VERSION ""

NS_ :

BS_:

BU_:

BO_ 65 FRS_Obj_Part2of2_Copy_39: 8 Vector__XXX
 SG_ FRS_Msg_CheckSum : 63|8@0+ (1,0) [0|255] "" Vector__XXX
 SG_ FRS_Msg_AliveCounter : 51|4@0+ (1,0) [0|15] "" Vector__XXX
 SG_ FRS_Obj_MeasFlag : 52|1@0+ (1,0) [0|1] "" Vector__XXX
 SG_ FRS_Obj_YVelRel : 47|11@0+ (0.1,-102.4) [-102.4|102.3] "m/s" Vector__XXX
 SG_ FRS_Obj_Type : 33|2@0+ (1,0) [0|3] "" Vector__XXX
 SG_ FRS_Obj_XPos : 31|14@0+ (0.015625,0) [0|255.984375] "m" Vector__XXX
 SG_ FRS_Obj_YPos : 12|13@0+ (0.015625,-64) [-64|63.984375] "m" Vector__XXX
 SG_ FRS_Obj_XVelRel : 7|11@0+ (0.1,-102.4) [-102.4|102.3] "m/s" Vector__XXX

BO_ 64 FRS_Obj_Part2of2_Copy_38: 8 Vector__XXX
 SG_ FRS_Msg_CheckSum : 63|8@0+ (1,0) [0|255] "" Vector__XXX
 SG_ FRS_Msg_AliveCounter : 51|4@0+ (1,0) [0|15] "" Vector__XXX
 SG_ FRS_Obj_MeasFlag : 52|1@0+ (1,0) [0|1] "" Vector__XXX
 SG_ FRS_Obj_YVelRel : 47|11@0+ (0.1,-102.4) [-102.4|102.3] "m/s" Vector__XXX
 SG_ FRS_Obj_Type : 33|2@0+ (1,0) [0|3] "" Vector__XXX
 SG_ FRS_Obj_XPos : 31|14@0+ (0.015625,0) [0|255.984375] "m" Vector__XXX
 SG_ FRS_Obj_YPos : 12|13@0+ (0.015625,-64) [-64|63.984375] "m" Vector__XXX
 SG_ FRS_Obj_XVelRel : 7|11@0+ (0.1,-102.4) [-102.4|102.3] "m/s" Vector__XXX

BO_ 63 FRS_Obj_Part2of2_Copy_37: 8 Vector__XXX
 SG_ FRS_Msg_CheckSum : 63|8@0+ (1,0) [0|255] "" Vector__XXX
 SG_ FRS_Msg_AliveCounter : 51|4@0+ (1,0) [0|15] "" Vector__XXX
 SG_ FRS_Obj_MeasFlag : 52|1@0+ (1,0) [0|1] "" Vector__XXX
 SG_ FRS_Obj_YVelRel : 47|11@0+ (0.1,-102.4) [-102.4|102.3] "m/s" Vector__XXX
 SG_ FRS_Obj_Type : 33|2@0+ (1,0) [0|3] "" Vector__XXX
 SG_ FRS_Obj_XPos : 31|14@0+ (0.015625,0) [0|255.984375] "m" Vector__XXX
 SG_ FRS_Obj_YPos : 12|13@0+ (0.015625,-64) [-64|63.984375] "m" Vector__XXX
 SG_ FRS_Obj_XVelRel : 7|11@0+ (0.1,-102.4) [-102.4|102.3] "m/s" Vector__XXX

BO_ 62 FRS_Obj_Part2of2_Copy_36: 8 Vector__XXX
 SG_ FRS_Msg_CheckSum : 63|8@0+ (1,0) [0|255] "" Vector__XXX
 SG_ FRS_Msg_AliveCounter : 51|4@0+ (1,0) [0|15] "" Vector__XXX
 SG_ FRS_Obj_MeasFlag : 52|1@0+ (1,0) [0|1] "" Vector__XXX
 SG_ FRS_Obj_YVelRel : 47|11@0+ (0.1,-102.4) [-102.4|102.3] "m/s" Vector__XXX
 SG_ FRS_Obj_Type : 33|2@0+ (1,0) [0|3] "" Vector__XXX
 SG_ FRS_Obj_XPos : 31|14@0+ (0.015625,0) [0|255.984375] "m" Vector__XXX
 SG_ FRS_Obj_YPos : 12|13@0+ (0.015625,-64) [-64|63.984375] "m" Vector__XXX
 SG_ FRS_Obj_XVelRel : 7|11@0+ (0.1,-102.4) [-102.4|102.3] "m/s" Vector__XXX

BO_ 61 FRS_Obj_Part2of2_Copy_35: 8 Vector__XXX
 SG_ FRS_Msg_CheckSum : 63|8@0+ (1,0) [0|255] "" Vector__XXX
 SG_ FRS_Msg_AliveCounter : 51|4@0+ (1,0) [0|15] "" Vector__XXX
 SG_ FRS_Obj_MeasFlag : 52|1@0+ (1,0) [0|1] "" Vector__XXX
 SG_ FRS_Obj_YVelRel : 47|11@0+ (0.1,-102.4) [-102.4|102.3] "m/s" Vector__XXX
 SG_ FRS_Obj_Type : 33|2@0+ (1,0) [0|3] "" Vector__XXX
 SG_ FRS_Obj_XPos : 31|14@0+ (0.015625,0) [0|255.984375] "m" Vector__XXX
 SG_ FRS_Obj_YPos : 12|13@0+ (0.015625,-64) [-64|63.984375] "m" Vector__XXX
 SG_ FRS_Obj_XVelRel : 7|11@0+ (0.1,-102.4) [-102.4|102.3] "m/s" Vector__XXX

BO_ 60 FRS_Obj_Part2of2_Copy_34: 8 Vector__XXX
 SG_ FRS_Msg_CheckSum : 63|8@0+ (1,0) [0|255] "" Vector__XXX
 SG_ FRS_Msg_AliveCounter : 51|4@0+ (1,0) [0|15] "" Vector__XXX
 SG_ FRS_Obj_MeasFlag : 52|1@0+ (1,0) [0|1] "" Vector__XXX
 SG_ FRS_Obj_YVelRel : 47|11@0+ (0.1,-102.4) [-102.4|102.3] "m/s" Vector__XXX
 SG_ FRS_Obj_Type : 33|2@0+ (1,0) [0|3] "" Vector__XXX
 SG_ FRS_Obj_XPos : 31|14@0+ (0.015625,0) [0|255.984375] "m" Vector__XXX
 SG_ FRS_Obj_YPos : 12|13@0+ (0.015625,-64) [-64|63.984375] "m" Vector__XXX
 SG_ FRS_Obj_XVelRel : 7|11@0+ (0.1,-102.4) [-102.4|102.3] "m/s" Vector__XXX

BO_ 59 FRS_Obj_Part2of2_Copy_33: 8 Vector__XXX
 SG_ FRS_Msg_CheckSum : 63|8@0+ (1,0) [0|255] "" Vector__XXX
 SG_ FRS_Msg_AliveCounter : 51|4@0+ (1,0) [0|15] "" Vector__XXX
 SG_ FRS_Obj_MeasFlag : 52|1@0+ (1,0) [0|1] "" Vector__XXX
 SG_ FRS_Obj_YVelRel : 47|11@0+ (0.1,-102.4) [-102.4|102.3] "m/s" Vector__XXX
 SG_ FRS_Obj_Type : 33|2@0+ (1,0) [0|3] "" Vector__XXX
 SG_ FRS_Obj_XPos : 31|14@0+ (0.015625,0) [0|255.984375] "m" Vector__XXX
 SG_ FRS_Obj_YPos : 12|13@0+ (0.015625,-64) [-64|63.984375] "m" Vector__XXX
 SG_ FRS_Obj_XVelRel : 7|11@0+ (0.1,-102.4) [-102.4|102.3] "m/s" Vector__XXX

BO_ 58 FRS_Obj_Part2of2_Copy_32: 8 Vector__XXX
 SG_ FRS_Msg_CheckSum : 63|8@0+ (1,0) [0|255] "" Vector__XXX
 SG_ FRS_Msg_AliveCounter : 51|4@0+ (1,0) [0|15] "" Vector__XXX
 SG_ FRS_Obj_MeasFlag : 52|1@0+ (1,0) [0|1] "" Vector__XXX
 SG_ FRS_Obj_YVelRel : 47|11@0+ (0.1,-102.4) [-102.4|102.3] "m/s" Vector__XXX
 SG_ FRS_Obj_Type : 33|2@0+ (1,0) [0|3] "" Vector__XXX
 SG_ FRS_Obj_XPos : 31|14@0+ (0.015625,0) [0|255.984375] "m" Vector__XXX
 SG_ FRS_Obj_YPos : 12|13@0+ (0.015625,-64) [-64|63.984375] "m" Vector__XXX
 SG_ FRS_Obj_XVelRel : 7|11@0+ (0.1,-102.4) [-102.4|102.3] "m/s" Vector__XXX

BO_ 57 FRS_Obj_Part2of2_Copy_31: 8 Vector__XXX
 SG_ FRS_Msg_CheckSum : 63|8@0+ (1,0) [0|255] "" Vector__XXX
 SG_ FRS_Msg_AliveCounter : 51|4@0+ (1,0) [0|15] "" Vector__XXX
 SG_ FRS_Obj_MeasFlag : 52|1@0+ (1,0) [0|1] "" Vector__XXX
 SG_ FRS_Obj_YVelRel : 47|11@0+ (0.1,-102.4) [-102.4|102.3] "m/s" Vector__XXX
 SG_ FRS_Obj_Type : 33|2@0+ (1,0) [0|3] "" Vector__XXX
 SG_ FRS_Obj_XPos : 31|14@0+ (0.015625,0) [0|255.984375] "m" Vector__XXX
 SG_ FRS_Obj_YPos : 12|13@0+ (0.015625,-64) [-64|63.984375] "m" Vector__XXX
 SG_ FRS_Obj_XVelRel : 7|11@0+ (0.1,-102.4) [-102.4|102.3] "m/s" Vector__XXX

BO_ 56 FRS_Obj_Part2of2_Copy_30: 8 Vector__XXX
 SG_ FRS_Msg_CheckSum : 63|8@0+ (1,0) [0|255] "" Vector__XXX
 SG_ FRS_Msg_AliveCounter : 51|4@0+ (1,0) [0|15] "" Vector__XXX
 SG_ FRS_Obj_MeasFlag : 52|1@0+ (1,0) [0|1] "" Vector__XXX
 SG_ FRS_Obj_YVelRel : 47|11@0+ (0.1,-102.4) [-102.4|102.3] "m/s" Vector__XXX
 SG_ FRS_Obj_Type : 33|2@0+ (1,0) [0|3] "" Vector__XXX
 SG_ FRS_Obj_XPos : 31|14@0+ (0.015625,0) [0|255.984375] "m" Vector__XXX
 SG_ FRS_Obj_YPos : 12|13@0+ (0.015625,-64) [-64|63.984375] "m" Vector__XXX
 SG_ FRS_Obj_XVelRel : 7|11@0+ (0.1,-102.4) [-102.4|102.3] "m/s" Vector__XXX

BO_ 54 FRS_Obj_Part2of2_Copy_29: 8 Vector__XXX
 SG_ FRS_Msg_CheckSum : 63|8@0+ (1,0) [0|255] "" Vector__XXX
 SG_ FRS_Msg_AliveCounter : 51|4@0+ (1,0) [0|15] "" Vector__XXX
 SG_ FRS_Obj_MeasFlag : 52|1@0+ (1,0) [0|1] "" Vector__XXX
 SG_ FRS_Obj_YVelRel : 47|11@0+ (0.1,-102.4) [-102.4|102.3] "m/s" Vector__XXX
 SG_ FRS_Obj_Type : 33|2@0+ (1,0) [0|3] "" Vector__XXX
 SG_ FRS_Obj_XPos : 31|14@0+ (0.015625,0) [0|255.984375] "m" Vector__XXX
 SG_ FRS_Obj_YPos : 12|13@0+ (0.015625,-64) [-64|63.984375] "m" Vector__XXX
 SG_ FRS_Obj_XVelRel : 7|11@0+ (0.1,-102.4) [-102.4|102.3] "m/s" Vector__XXX

BO_ 53 FRS_Obj_Part2of2_Copy_28: 8 Vector__XXX
 SG_ FRS_Msg_CheckSum : 63|8@0+ (1,0) [0|255] "" Vector__XXX
 SG_ FRS_Msg_AliveCounter : 51|4@0+ (1,0) [0|15] "" Vector__XXX
 SG_ FRS_Obj_MeasFlag : 52|1@0+ (1,0) [0|1] "" Vector__XXX
 SG_ FRS_Obj_YVelRel : 47|11@0+ (0.1,-102.4) [-102.4|102.3] "m/s" Vector__XXX
 SG_ FRS_Obj_Type : 33|2@0+ (1,0) [0|3] "" Vector__XXX
 SG_ FRS_Obj_XPos : 31|14@0+ (0.015625,0) [0|255.984375] "m" Vector__XXX
 SG_ FRS_Obj_YPos : 12|13@0+ (0.015625,-64) [-64|63.984375] "m" Vector__XXX
 SG_ FRS_Obj_XVelRel : 7|11@0+ (0.1,-102.4) [-102.4|102.3] "m/s" Vector__XXX

BO_ 52 FRS_Obj_Part2of2_Copy_27: 8 Vector__XXX
 SG_ FRS_Msg_CheckSum : 63|8@0+ (1,0) [0|255] "" Vector__XXX
 SG_ FRS_Msg_AliveCounter : 51|4@0+ (1,0) [0|15] "" Vector__XXX
 SG_ FRS_Obj_MeasFlag : 52|1@0+ (1,0) [0|1] "" Vector__XXX
 SG_ FRS_Obj_YVelRel : 47|11@0+ (0.1,-102.4) [-102.4|102.3] "m/s" Vector__XXX
 SG_ FRS_Obj_Type : 33|2@0+ (1,0) [0|3] "" Vector__XXX
 SG_ FRS_Obj_XPos : 31|14@0+ (0.015625,0) [0|255.984375] "m" Vector__XXX
 SG_ FRS_Obj_YPos : 12|13@0+ (0.015625,-64) [-64|63.984375] "m" Vector__XXX
 SG_ FRS_Obj_XVelRel : 7|11@0+ (0.1,-102.4) [-102.4|102.3] "m/s" Vector__XXX

BO_ 51 FRS_Obj_Part2of2_Copy_26: 8 Vector__XXX
 SG_ FRS_Msg_CheckSum : 63|8@0+ (1,0) [0|255] "" Vector__XXX
 SG_ FRS_Msg_AliveCounter : 51|4@0+ (1,0) [0|15] "" Vector__XXX
 SG_ FRS_Obj_MeasFlag : 52|1@0+ (1,0) [0|1] "" Vector__XXX
 SG_ FRS_Obj_YVelRel : 47|11@0+ (0.1,-102.4) [-102.4|102.3] "m/s" Vector__XXX
 SG_ FRS_Obj_Type : 33|2@0+ (1,0) [0|3] "" Vector__XXX
 SG_ FRS_Obj_XPos : 31|14@0+ (0.015625,0) [0|255.984375] "m" Vector__XXX
 SG_ FRS_Obj_YPos : 12|13@0+ (0.015625,-64) [-64|63.984375] "m" Vector__XXX
 SG_ FRS_Obj_XVelRel : 7|11@0+ (0.1,-102.4) [-102.4|102.3] "m/s" Vector__XXX

BO_ 50 FRS_Obj_Part2of2_Copy_25: 8 Vector__XXX
 SG_ FRS_Msg_CheckSum : 63|8@0+ (1,0) [0|255] "" Vector__XXX
 SG_ FRS_Msg_AliveCounter : 51|4@0+ (1,0) [0|15] "" Vector__XXX
 SG_ FRS_Obj_MeasFlag : 52|1@0+ (1,0) [0|1] "" Vector__XXX
 SG_ FRS_Obj_YVelRel : 47|11@0+ (0.1,-102.4) [-102.4|102.3] "m/s" Vector__XXX
 SG_ FRS_Obj_Type : 33|2@0+ (1,0) [0|3] "" Vector__XXX
 SG_ FRS_Obj_XPos : 31|14@0+ (0.015625,0) [0|255.984375] "m" Vector__XXX
 SG_ FRS_Obj_YPos : 12|13@0+ (0.015625,-64) [-64|63.984375] "m" Vector__XXX
 SG_ FRS_Obj_XVelRel : 7|11@0+ (0.1,-102.4) [-102.4|102.3] "m/s" Vector__XXX

BO_ 49 FRS_Obj_Part2of2_Copy_24: 8 Vector__XXX
 SG_ FRS_Msg_CheckSum : 63|8@0+ (1,0) [0|255] "" Vector__XXX
 SG_ FRS_Msg_AliveCounter : 51|4@0+ (1,0) [0|15] "" Vector__XXX
 SG_ FRS_Obj_MeasFlag : 52|1@0+ (1,0) [0|1] "" Vector__XXX
 SG_ FRS_Obj_YVelRel : 47|11@0+ (0.1,-102.4) [-102.4|102.3] "m/s" Vector__XXX
 SG_ FRS_Obj_Type : 33|2@0+ (1,0) [0|3] "" Vector__XXX
 SG_ FRS_Obj_XPos : 31|14@0+ (0.015625,0) [0|255.984375] "m" Vector__XXX
 SG_ FRS_Obj_YPos : 12|13@0+ (0.015625,-64) [-64|63.984375] "m" Vector__XXX
 SG_ FRS_Obj_XVelRel : 7|11@0+ (0.1,-102.4) [-102.4|102.3] "m/s" Vector__XXX

BO_ 48 FRS_Obj_Part2of2_Copy_23: 8 Vector__XXX
 SG_ FRS_Msg_CheckSum : 63|8@0+ (1,0) [0|255] "" Vector__XXX
 SG_ FRS_Msg_AliveCounter : 51|4@0+ (1,0) [0|15] "" Vector__XXX
 SG_ FRS_Obj_MeasFlag : 52|1@0+ (1,0) [0|1] "" Vector__XXX
 SG_ FRS_Obj_YVelRel : 47|11@0+ (0.1,-102.4) [-102.4|102.3] "m/s" Vector__XXX
 SG_ FRS_Obj_Type : 33|2@0+ (1,0) [0|3] "" Vector__XXX
 SG_ FRS_Obj_XPos : 31|14@0+ (0.015625,0) [0|255.984375] "m" Vector__XXX
 SG_ FRS_Obj_YPos : 12|13@0+ (0.015625,-64) [-64|63.984375] "m" Vector__XXX
 SG_ FRS_Obj_XVelRel : 7|11@0+ (0.1,-102.4) [-102.4|102.3] "m/s" Vector__XXX

BO_ 47 FRS_Obj_Part2of2_Copy_22: 8 Vector__XXX
 SG_ FRS_Msg_CheckSum : 63|8@0+ (1,0) [0|255] "" Vector__XXX
 SG_ FRS_Msg_AliveCounter : 51|4@0+ (1,0) [0|15] "" Vector__XXX
 SG_ FRS_Obj_MeasFlag : 52|1@0+ (1,0) [0|1] "" Vector__XXX
 SG_ FRS_Obj_YVelRel : 47|11@0+ (0.1,-102.4) [-102.4|102.3] "m/s" Vector__XXX
 SG_ FRS_Obj_Type : 33|2@0+ (1,0) [0|3] "" Vector__XXX
 SG_ FRS_Obj_XPos : 31|14@0+ (0.015625,0) [0|255.984375] "m" Vector__XXX
 SG_ FRS_Obj_YPos : 12|13@0+ (0.015625,-64) [-64|63.984375] "m" Vector__XXX
 SG_ FRS_Obj_XVelRel : 7|11@0+ (0.1,-102.4) [-102.4|102.3] "m/s" Vector__XXX

BO_ 46 FRS_Obj_Part2of2_Copy_21: 8 Vector__XXX
 SG_ FRS_Msg_CheckSum : 63|8@0+ (1,0) [0|255] "" Vector__XXX
 SG_ FRS_Msg_AliveCounter : 51|4@0+ (1,0) [0|15] "" Vector__XXX
 SG_ FRS_Obj_MeasFlag : 52|1@0+ (1,0) [0|1] "" Vector__XXX
 SG_ FRS_Obj_YVelRel : 47|11@0+ (0.1,-102.4) [-102.4|102.3] "m/s" Vector__XXX
 SG_ FRS_Obj_Type : 33|2@0+ (1,0) [0|3] "" Vector__XXX
 SG_ FRS_Obj_XPos : 31|14@0+ (0.015625,0) [0|255.984375] "m" Vector__XXX
 SG_ FRS_Obj_YPos : 12|13@0+ (0.015625,-64) [-64|63.984375] "m" Vector__XXX
 SG_ FRS_Obj_XVelRel : 7|11@0+ (0.1,-102.4) [-102.4|102.3] "m/s" Vector__XXX

BO_ 45 FRS_Obj_Part2of2_Copy_20: 8 Vector__XXX
 SG_ FRS_Msg_CheckSum : 63|8@0+ (1,0) [0|255] "" Vector__XXX
 SG_ FRS_Msg_AliveCounter : 51|4@0+ (1,0) [0|15] "" Vector__XXX
 SG_ FRS_Obj_MeasFlag : 52|1@0+ (1,0) [0|1] "" Vector__XXX
 SG_ FRS_Obj_YVelRel : 47|11@0+ (0.1,-102.4) [-102.4|102.3] "m/s" Vector__XXX
 SG_ FRS_Obj_Type : 33|2@0+ (1,0) [0|3] "" Vector__XXX
 SG_ FRS_Obj_XPos : 31|14@0+ (0.015625,0) [0|255.984375] "m" Vector__XXX
 SG_ FRS_Obj_YPos : 12|13@0+ (0.015625,-64) [-64|63.984375] "m" Vector__XXX
 SG_ FRS_Obj_XVelRel : 7|11@0+ (0.1,-102.4) [-102.4|102.3] "m/s" Vector__XXX

BO_ 43 FRS_Obj_Part2of2_Copy_19: 8 Vector__XXX
 SG_ FRS_Msg_CheckSum : 63|8@0+ (1,0) [0|255] "" Vector__XXX
 SG_ FRS_Msg_AliveCounter : 51|4@0+ (1,0) [0|15] "" Vector__XXX
 SG_ FRS_Obj_MeasFlag : 52|1@0+ (1,0) [0|1] "" Vector__XXX
 SG_ FRS_Obj_YVelRel : 47|11@0+ (0.1,-102.4) [-102.4|102.3] "m/s" Vector__XXX
 SG_ FRS_Obj_Type : 33|2@0+ (1,0) [0|3] "" Vector__XXX
 SG_ FRS_Obj_XPos : 31|14@0+ (0.015625,0) [0|255.984375] "m" Vector__XXX
 SG_ FRS_Obj_YPos : 12|13@0+ (0.015625,-64) [-64|63.984375] "m" Vector__XXX
 SG_ FRS_Obj_XVelRel : 7|11@0+ (0.1,-102.4) [-102.4|102.3] "m/s" Vector__XXX

BO_ 42 FRS_Obj_Part2of2_Copy_18: 8 Vector__XXX
 SG_ FRS_Msg_CheckSum : 63|8@0+ (1,0) [0|255] "" Vector__XXX
 SG_ FRS_Msg_AliveCounter : 51|4@0+ (1,0) [0|15] "" Vector__XXX
 SG_ FRS_Obj_MeasFlag : 52|1@0+ (1,0) [0|1] "" Vector__XXX
 SG_ FRS_Obj_YVelRel : 47|11@0+ (0.1,-102.4) [-102.4|102.3] "m/s" Vector__XXX
 SG_ FRS_Obj_Type : 33|2@0+ (1,0) [0|3] "" Vector__XXX
 SG_ FRS_Obj_XPos : 31|14@0+ (0.015625,0) [0|255.984375] "m" Vector__XXX
 SG_ FRS_Obj_YPos : 12|13@0+ (0.015625,-64) [-64|63.984375] "m" Vector__XXX
 SG_ FRS_Obj_XVelRel : 7|11@0+ (0.1,-102.4) [-102.4|102.3] "m/s" Vector__XXX

BO_ 41 FRS_Obj_Part2of2_Copy_17: 8 Vector__XXX
 SG_ FRS_Msg_CheckSum : 63|8@0+ (1,0) [0|255] "" Vector__XXX
 SG_ FRS_Msg_AliveCounter : 51|4@0+ (1,0) [0|15] "" Vector__XXX
 SG_ FRS_Obj_MeasFlag : 52|1@0+ (1,0) [0|1] "" Vector__XXX
 SG_ FRS_Obj_YVelRel : 47|11@0+ (0.1,-102.4) [-102.4|102.3] "m/s" Vector__XXX
 SG_ FRS_Obj_Type : 33|2@0+ (1,0) [0|3] "" Vector__XXX
 SG_ FRS_Obj_XPos : 31|14@0+ (0.015625,0) [0|255.984375] "m" Vector__XXX
 SG_ FRS_Obj_YPos : 12|13@0+ (0.015625,-64) [-64|63.984375] "m" Vector__XXX
 SG_ FRS_Obj_XVelRel : 7|11@0+ (0.1,-102.4) [-102.4|102.3] "m/s" Vector__XXX

BO_ 40 FRS_Obj_Part2of2_Copy_16: 8 Vector__XXX
 SG_ FRS_Msg_CheckSum : 63|8@0+ (1,0) [0|255] "" Vector__XXX
 SG_ FRS_Msg_AliveCounter : 51|4@0+ (1,0) [0|15] "" Vector__XXX
 SG_ FRS_Obj_MeasFlag : 52|1@0+ (1,0) [0|1] "" Vector__XXX
 SG_ FRS_Obj_YVelRel : 47|11@0+ (0.1,-102.4) [-102.4|102.3] "m/s" Vector__XXX
 SG_ FRS_Obj_Type : 33|2@0+ (1,0) [0|3] "" Vector__XXX
 SG_ FRS_Obj_XPos : 31|14@0+ (0.015625,0) [0|255.984375] "m" Vector__XXX
 SG_ FRS_Obj_YPos : 12|13@0+ (0.015625,-64) [-64|63.984375] "m" Vector__XXX
 SG_ FRS_Obj_XVelRel : 7|11@0+ (0.1,-102.4) [-102.4|102.3] "m/s" Vector__XXX

BO_ 39 FRS_Obj_Part2of2_Copy_15: 8 Vector__XXX
 SG_ FRS_Msg_CheckSum : 63|8@0+ (1,0) [0|255] "" Vector__XXX
 SG_ FRS_Msg_AliveCounter : 51|4@0+ (1,0) [0|15] "" Vector__XXX
 SG_ FRS_Obj_MeasFlag : 52|1@0+ (1,0) [0|1] "" Vector__XXX
 SG_ FRS_Obj_YVelRel : 47|11@0+ (0.1,-102.4) [-102.4|102.3] "m/s" Vector__XXX
 SG_ FRS_Obj_Type : 33|2@0+ (1,0) [0|3] "" Vector__XXX
 SG_ FRS_Obj_XPos : 31|14@0+ (0.015625,0) [0|255.984375] "m" Vector__XXX
 SG_ FRS_Obj_YPos : 12|13@0+ (0.015625,-64) [-64|63.984375] "m" Vector__XXX
 SG_ FRS_Obj_XVelRel : 7|11@0+ (0.1,-102.4) [-102.4|102.3] "m/s" Vector__XXX

BO_ 38 FRS_Obj_Part2of2_Copy_14: 8 Vector__XXX
 SG_ FRS_Msg_CheckSum : 63|8@0+ (1,0) [0|255] "" Vector__XXX
 SG_ FRS_Msg_AliveCounter : 51|4@0+ (1,0) [0|15] "" Vector__XXX
 SG_ FRS_Obj_MeasFlag : 52|1@0+ (1,0) [0|1] "" Vector__XXX
 SG_ FRS_Obj_YVelRel : 47|11@0+ (0.1,-102.4) [-102.4|102.3] "m/s" Vector__XXX
 SG_ FRS_Obj_Type : 33|2@0+ (1,0) [0|3] "" Vector__XXX
 SG_ FRS_Obj_XPos : 31|14@0+ (0.015625,0) [0|255.984375] "m" Vector__XXX
 SG_ FRS_Obj_YPos : 12|13@0+ (0.015625,-64) [-64|63.984375] "m" Vector__XXX
 SG_ FRS_Obj_XVelRel : 7|11@0+ (0.1,-102.4) [-102.4|102.3] "m/s" Vector__XXX

BO_ 37 FRS_Obj_Part2of2_Copy_13: 8 Vector__XXX
 SG_ FRS_Msg_CheckSum : 63|8@0+ (1,0) [0|255] "" Vector__XXX
 SG_ FRS_Msg_AliveCounter : 51|4@0+ (1,0) [0|15] "" Vector__XXX
 SG_ FRS_Obj_MeasFlag : 52|1@0+ (1,0) [0|1] "" Vector__XXX
 SG_ FRS_Obj_YVelRel : 47|11@0+ (0.1,-102.4) [-102.4|102.3] "m/s" Vector__XXX
 SG_ FRS_Obj_Type : 33|2@0+ (1,0) [0|3] "" Vector__XXX
 SG_ FRS_Obj_XPos : 31|14@0+ (0.015625,0) [0|255.984375] "m" Vector__XXX
 SG_ FRS_Obj_YPos : 12|13@0+ (0.015625,-64) [-64|63.984375] "m" Vector__XXX
 SG_ FRS_Obj_XVelRel : 7|11@0+ (0.1,-102.4) [-102.4|102.3] "m/s" Vector__XXX

BO_ 36 FRS_Obj_Part2of2_Copy_12: 8 Vector__XXX
 SG_ FRS_Msg_CheckSum : 63|8@0+ (1,0) [0|255] "" Vector__XXX
 SG_ FRS_Msg_AliveCounter : 51|4@0+ (1,0) [0|15] "" Vector__XXX
 SG_ FRS_Obj_MeasFlag : 52|1@0+ (1,0) [0|1] "" Vector__XXX
 SG_ FRS_Obj_YVelRel : 47|11@0+ (0.1,-102.4) [-102.4|102.3] "m/s" Vector__XXX
 SG_ FRS_Obj_Type : 33|2@0+ (1,0) [0|3] "" Vector__XXX
 SG_ FRS_Obj_XPos : 31|14@0+ (0.015625,0) [0|255.984375] "m" Vector__XXX
 SG_ FRS_Obj_YPos : 12|13@0+ (0.015625,-64) [-64|63.984375] "m" Vector__XXX
 SG_ FRS_Obj_XVelRel : 7|11@0+ (0.1,-102.4) [-102.4|102.3] "m/s" Vector__XXX

BO_ 35 FRS_Obj_Part2of2_Copy_11: 8 Vector__XXX
 SG_ FRS_Msg_CheckSum : 63|8@0+ (1,0) [0|255] "" Vector__XXX
 SG_ FRS_Msg_AliveCounter : 51|4@0+ (1,0) [0|15] "" Vector__XXX
 SG_ FRS_Obj_MeasFlag : 52|1@0+ (1,0) [0|1] "" Vector__XXX
 SG_ FRS_Obj_YVelRel : 47|11@0+ (0.1,-102.4) [-102.4|102.3] "m/s" Vector__XXX
 SG_ FRS_Obj_Type : 33|2@0+ (1,0) [0|3] "" Vector__XXX
 SG_ FRS_Obj_XPos : 31|14@0+ (0.015625,0) [0|255.984375] "m" Vector__XXX
 SG_ FRS_Obj_YPos : 12|13@0+ (0.015625,-64) [-64|63.984375] "m" Vector__XXX
 SG_ FRS_Obj_XVelRel : 7|11@0+ (0.1,-102.4) [-102.4|102.3] "m/s" Vector__XXX

BO_ 34 FRS_Obj_Part2of2_Copy_10: 8 Vector__XXX
 SG_ FRS_Msg_CheckSum : 63|8@0+ (1,0) [0|255] "" Vector__XXX
 SG_ FRS_Msg_AliveCounter : 51|4@0+ (1,0) [0|15] "" Vector__XXX
 SG_ FRS_Obj_MeasFlag : 52|1@0+ (1,0) [0|1] "" Vector__XXX
 SG_ FRS_Obj_YVelRel : 47|11@0+ (0.1,-102.4) [-102.4|102.3] "m/s" Vector__XXX
 SG_ FRS_Obj_Type : 33|2@0+ (1,0) [0|3] "" Vector__XXX
 SG_ FRS_Obj_XPos : 31|14@0+ (0.015625,0) [0|255.984375] "m" Vector__XXX
 SG_ FRS_Obj_YPos : 12|13@0+ (0.015625,-64) [-64|63.984375] "m" Vector__XXX
 SG_ FRS_Obj_XVelRel : 7|11@0+ (0.1,-102.4) [-102.4|102.3] "m/s" Vector__XXX

BO_ 71 FRS_Obj_Part2of2_Copy_9: 8 Vector__XXX
 SG_ FRS_Msg_CheckSum : 63|8@0+ (1,0) [0|255] "" Vector__XXX
 SG_ FRS_Msg_AliveCounter : 51|4@0+ (1,0) [0|15] "" Vector__XXX
 SG_ FRS_Obj_MeasFlag : 52|1@0+ (1,0) [0|1] "" Vector__XXX
 SG_ FRS_Obj_YVelRel : 47|11@0+ (0.1,-102.4) [-102.4|102.3] "m/s" Vector__XXX
 SG_ FRS_Obj_Type : 33|2@0+ (1,0) [0|3] "" Vector__XXX
 SG_ FRS_Obj_XPos : 31|14@0+ (0.015625,0) [0|255.984375] "m" Vector__XXX
 SG_ FRS_Obj_YPos : 12|13@0+ (0.015625,-64) [-64|63.984375] "m" Vector__XXX
 SG_ FRS_Obj_XVelRel : 7|11@0+ (0.1,-102.4) [-102.4|102.3] "m/s" Vector__XXX

BO_ 70 FRS_Obj_Part2of2_Copy_8: 8 Vector__XXX
 SG_ FRS_Msg_CheckSum : 63|8@0+ (1,0) [0|255] "" Vector__XXX
 SG_ FRS_Msg_AliveCounter : 51|4@0+ (1,0) [0|15] "" Vector__XXX
 SG_ FRS_Obj_MeasFlag : 52|1@0+ (1,0) [0|1] "" Vector__XXX
 SG_ FRS_Obj_YVelRel : 47|11@0+ (0.1,-102.4) [-102.4|102.3] "m/s" Vector__XXX
 SG_ FRS_Obj_Type : 33|2@0+ (1,0) [0|3] "" Vector__XXX
 SG_ FRS_Obj_XPos : 31|14@0+ (0.015625,0) [0|255.984375] "m" Vector__XXX
 SG_ FRS_Obj_YPos : 12|13@0+ (0.015625,-64) [-64|63.984375] "m" Vector__XXX
 SG_ FRS_Obj_XVelRel : 7|11@0+ (0.1,-102.4) [-102.4|102.3] "m/s" Vector__XXX

BO_ 69 FRS_Obj_Part2of2_Copy_7: 8 Vector__XXX
 SG_ FRS_Msg_CheckSum : 63|8@0+ (1,0) [0|255] "" Vector__XXX
 SG_ FRS_Msg_AliveCounter : 51|4@0+ (1,0) [0|15] "" Vector__XXX
 SG_ FRS_Obj_MeasFlag : 52|1@0+ (1,0) [0|1] "" Vector__XXX
 SG_ FRS_Obj_YVelRel : 47|11@0+ (0.1,-102.4) [-102.4|102.3] "m/s" Vector__XXX
 SG_ FRS_Obj_Type : 33|2@0+ (1,0) [0|3] "" Vector__XXX
 SG_ FRS_Obj_XPos : 31|14@0+ (0.015625,0) [0|255.984375] "m" Vector__XXX
 SG_ FRS_Obj_YPos : 12|13@0+ (0.015625,-64) [-64|63.984375] "m" Vector__XXX
 SG_ FRS_Obj_XVelRel : 7|11@0+ (0.1,-102.4) [-102.4|102.3] "m/s" Vector__XXX

BO_ 68 FRS_Obj_Part2of2_Copy_6: 8 Vector__XXX
 SG_ FRS_Msg_CheckSum : 63|8@0+ (1,0) [0|255] "" Vector__XXX
 SG_ FRS_Msg_AliveCounter : 51|4@0+ (1,0) [0|15] "" Vector__XXX
 SG_ FRS_Obj_MeasFlag : 52|1@0+ (1,0) [0|1] "" Vector__XXX
 SG_ FRS_Obj_YVelRel : 47|11@0+ (0.1,-102.4) [-102.4|102.3] "m/s" Vector__XXX
 SG_ FRS_Obj_Type : 33|2@0+ (1,0) [0|3] "" Vector__XXX
 SG_ FRS_Obj_XPos : 31|14@0+ (0.015625,0) [0|255.984375] "m" Vector__XXX
 SG_ FRS_Obj_YPos : 12|13@0+ (0.015625,-64) [-64|63.984375] "m" Vector__XXX
 SG_ FRS_Obj_XVelRel : 7|11@0+ (0.1,-102.4) [-102.4|102.3] "m/s" Vector__XXX

BO_ 67 FRS_Obj_Part2of2_Copy_5: 8 Vector__XXX
 SG_ FRS_Msg_CheckSum : 63|8@0+ (1,0) [0|255] "" Vector__XXX
 SG_ FRS_Msg_AliveCounter : 51|4@0+ (1,0) [0|15] "" Vector__XXX
 SG_ FRS_Obj_MeasFlag : 52|1@0+ (1,0) [0|1] "" Vector__XXX
 SG_ FRS_Obj_YVelRel : 47|11@0+ (0.1,-102.4) [-102.4|102.3] "m/s" Vector__XXX
 SG_ FRS_Obj_Type : 33|2@0+ (1,0) [0|3] "" Vector__XXX
 SG_ FRS_Obj_XPos : 31|14@0+ (0.015625,0) [0|255.984375] "m" Vector__XXX
 SG_ FRS_Obj_YPos : 12|13@0+ (0.015625,-64) [-64|63.984375] "m" Vector__XXX
 SG_ FRS_Obj_XVelRel : 7|11@0+ (0.1,-102.4) [-102.4|102.3] "m/s" Vector__XXX

BO_ 66 FRS_Obj_Part2of2_Copy_4: 8 Vector__XXX
 SG_ FRS_Msg_CheckSum : 63|8@0+ (1,0) [0|255] "" Vector__XXX
 SG_ FRS_Msg_AliveCounter : 51|4@0+ (1,0) [0|15] "" Vector__XXX
 SG_ FRS_Obj_MeasFlag : 52|1@0+ (1,0) [0|1] "" Vector__XXX
 SG_ FRS_Obj_YVelRel : 47|11@0+ (0.1,-102.4) [-102.4|102.3] "m/s" Vector__XXX
 SG_ FRS_Obj_Type : 33|2@0+ (1,0) [0|3] "" Vector__XXX
 SG_ FRS_Obj_XPos : 31|14@0+ (0.015625,0) [0|255.984375] "m" Vector__XXX
 SG_ FRS_Obj_YPos : 12|13@0+ (0.015625,-64) [-64|63.984375] "m" Vector__XXX
 SG_ FRS_Obj_XVelRel : 7|11@0+ (0.1,-102.4) [-102.4|102.3] "m/s" Vector__XXX

BO_ 55 FRS_Obj_Part2of2_Copy_3: 8 Vector__XXX
 SG_ FRS_Msg_CheckSum : 63|8@0+ (1,0) [0|255] "" Vector__XXX
 SG_ FRS_Msg_AliveCounter : 51|4@0+ (1,0) [0|15] "" Vector__XXX
 SG_ FRS_Obj_MeasFlag : 52|1@0+ (1,0) [0|1] "" Vector__XXX
 SG_ FRS_Obj_YVelRel : 47|11@0+ (0.1,-102.4) [-102.4|102.3] "m/s" Vector__XXX
 SG_ FRS_Obj_Type : 33|2@0+ (1,0) [0|3] "" Vector__XXX
 SG_ FRS_Obj_XPos : 31|14@0+ (0.015625,0) [0|255.984375] "m" Vector__XXX
 SG_ FRS_Obj_YPos : 12|13@0+ (0.015625,-64) [-64|63.984375] "m" Vector__XXX
 SG_ FRS_Obj_XVelRel : 7|11@0+ (0.1,-102.4) [-102.4|102.3] "m/s" Vector__XXX

BO_ 44 FRS_Obj_Part2of2_Copy_2: 8 Vector__XXX
 SG_ FRS_Msg_CheckSum : 63|8@0+ (1,0) [0|255] "" Vector__XXX
 SG_ FRS_Msg_AliveCounter : 51|4@0+ (1,0) [0|15] "" Vector__XXX
 SG_ FRS_Obj_MeasFlag : 52|1@0+ (1,0) [0|1] "" Vector__XXX
 SG_ FRS_Obj_YVelRel : 47|11@0+ (0.1,-102.4) [-102.4|102.3] "m/s" Vector__XXX
 SG_ FRS_Obj_Type : 33|2@0+ (1,0) [0|3] "" Vector__XXX
 SG_ FRS_Obj_XPos : 31|14@0+ (0.015625,0) [0|255.984375] "m" Vector__XXX
 SG_ FRS_Obj_YPos : 12|13@0+ (0.015625,-64) [-64|63.984375] "m" Vector__XXX
 SG_ FRS_Obj_XVelRel : 7|11@0+ (0.1,-102.4) [-102.4|102.3] "m/s" Vector__XXX

BO_ 33 FRS_Obj_Part2of2_Copy_1: 8 Vector__XXX
 SG_ FRS_Msg_CheckSum : 63|8@0+ (1,0) [0|255] "" Vector__XXX
 SG_ FRS_Msg_AliveCounter : 51|4@0+ (1,0) [0|15] "" Vector__XXX
 SG_ FRS_Obj_MeasFlag : 52|1@0+ (1,0) [0|1] "" Vector__XXX
 SG_ FRS_Obj_YVelRel : 47|11@0+ (0.1,-102.4) [-102.4|102.3] "m/s" Vector__XXX
 SG_ FRS_Obj_Type : 33|2@0+ (1,0) [0|3] "" Vector__XXX
 SG_ FRS_Obj_XPos : 31|14@0+ (0.015625,0) [0|255.984375] "m" Vector__XXX
 SG_ FRS_Obj_YPos : 12|13@0+ (0.015625,-64) [-64|63.984375] "m" Vector__XXX
 SG_ FRS_Obj_XVelRel : 7|11@0+ (0.1,-102.4) [-102.4|102.3] "m/s" Vector__XXX

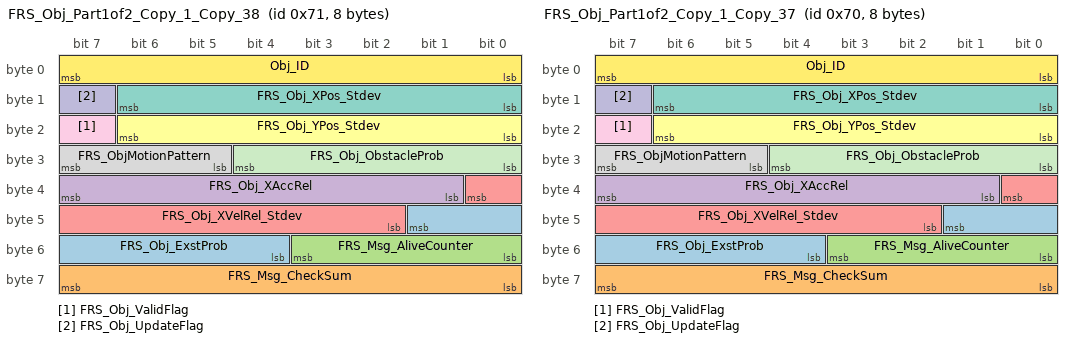
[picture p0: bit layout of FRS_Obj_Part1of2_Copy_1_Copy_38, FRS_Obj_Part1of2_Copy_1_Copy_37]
BO_ 113 FRS_Obj_Part1of2_Copy_1_Copy_38: 8 Vector__XXX
 SG_ FRS_Obj_ExstProb : 41|6@0+ (1.587,0) [0|100] "%" Vector__XXX
 SG_ FRS_Msg_CheckSum : 63|8@0+ (1,0) [0|255] "" Vector__XXX
 SG_ FRS_Msg_AliveCounter : 51|4@0+ (1,0) [0|15] "" Vector__XXX
 SG_ FRS_Obj_XAccRel : 39|7@0+ (0.15,-9.6) [-9.6|9.45] "m/s2" Vector__XXX
 SG_ FRS_Obj_XVelRel_Stdev : 32|7@0+ (0.05,0) [0|6.35] "m/s" Vector__XXX
 SG_ FRS_Obj_YPos_Stdev : 22|7@0+ (0.1,0) [0|12.7] "m" Vector__XXX
 SG_ FRS_Obj_XPos_Stdev : 14|7@0+ (0.1,0) [0|12.7] "m" Vector__XXX
 SG_ FRS_ObjMotionPattern : 31|3@0+ (1,0) [0|7] "" Vector__XXX
 SG_ FRS_Obj_ValidFlag : 23|1@0+ (1,0) [0|1] "" Vector__XXX
 SG_ FRS_Obj_UpdateFlag : 15|1@0+ (1,0) [0|1] "" Vector__XXX
 SG_ FRS_Obj_ObstacleProb : 28|5@0+ (3.226,0) [0|100] "%" Vector__XXX
 SG_ Obj_ID : 7|8@0+ (1,0) [0|255] "" Vector__XXX

BO_ 112 FRS_Obj_Part1of2_Copy_1_Copy_37: 8 Vector__XXX
 SG_ FRS_Obj_ExstProb : 41|6@0+ (1.587,0) [0|100] "%" Vector__XXX
 SG_ FRS_Msg_CheckSum : 63|8@0+ (1,0) [0|255] "" Vector__XXX
 SG_ FRS_Msg_AliveCounter : 51|4@0+ (1,0) [0|15] "" Vector__XXX
 SG_ FRS_Obj_XAccRel : 39|7@0+ (0.15,-9.6) [-9.6|9.45] "m/s2" Vector__XXX
 SG_ FRS_Obj_XVelRel_Stdev : 32|7@0+ (0.05,0) [0|6.35] "m/s" Vector__XXX
 SG_ FRS_Obj_YPos_Stdev : 22|7@0+ (0.1,0) [0|12.7] "m" Vector__XXX
 SG_ FRS_Obj_XPos_Stdev : 14|7@0+ (0.1,0) [0|12.7] "m" Vector__XXX
 SG_ FRS_ObjMotionPattern : 31|3@0+ (1,0) [0|7] "" Vector__XXX
 SG_ FRS_Obj_ValidFlag : 23|1@0+ (1,0) [0|1] "" Vector__XXX
 SG_ FRS_Obj_UpdateFlag : 15|1@0+ (1,0) [0|1] "" Vector__XXX
 SG_ FRS_Obj_ObstacleProb : 28|5@0+ (3.226,0) [0|100] "%" Vector__XXX
 SG_ Obj_ID : 7|8@0+ (1,0) [0|255] "" Vector__XXX

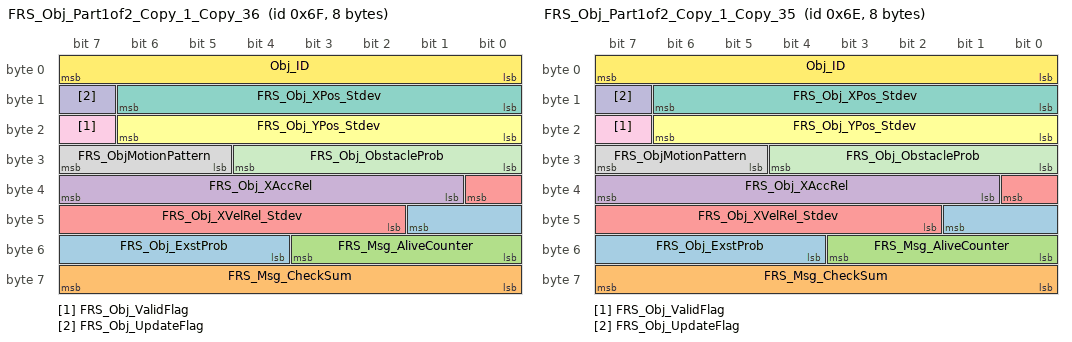
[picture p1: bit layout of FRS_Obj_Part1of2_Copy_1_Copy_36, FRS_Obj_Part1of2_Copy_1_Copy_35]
BO_ 111 FRS_Obj_Part1of2_Copy_1_Copy_36: 8 Vector__XXX
 SG_ FRS_Obj_ExstProb : 41|6@0+ (1.587,0) [0|100] "%" Vector__XXX
 SG_ FRS_Msg_CheckSum : 63|8@0+ (1,0) [0|255] "" Vector__XXX
 SG_ FRS_Msg_AliveCounter : 51|4@0+ (1,0) [0|15] "" Vector__XXX
 SG_ FRS_Obj_XAccRel : 39|7@0+ (0.15,-9.6) [-9.6|9.45] "m/s2" Vector__XXX
 SG_ FRS_Obj_XVelRel_Stdev : 32|7@0+ (0.05,0) [0|6.35] "m/s" Vector__XXX
 SG_ FRS_Obj_YPos_Stdev : 22|7@0+ (0.1,0) [0|12.7] "m" Vector__XXX
 SG_ FRS_Obj_XPos_Stdev : 14|7@0+ (0.1,0) [0|12.7] "m" Vector__XXX
 SG_ FRS_ObjMotionPattern : 31|3@0+ (1,0) [0|7] "" Vector__XXX
 SG_ FRS_Obj_ValidFlag : 23|1@0+ (1,0) [0|1] "" Vector__XXX
 SG_ FRS_Obj_UpdateFlag : 15|1@0+ (1,0) [0|1] "" Vector__XXX
 SG_ FRS_Obj_ObstacleProb : 28|5@0+ (3.226,0) [0|100] "%" Vector__XXX
 SG_ Obj_ID : 7|8@0+ (1,0) [0|255] "" Vector__XXX

BO_ 110 FRS_Obj_Part1of2_Copy_1_Copy_35: 8 Vector__XXX
 SG_ FRS_Obj_ExstProb : 41|6@0+ (1.587,0) [0|100] "%" Vector__XXX
 SG_ FRS_Msg_CheckSum : 63|8@0+ (1,0) [0|255] "" Vector__XXX
 SG_ FRS_Msg_AliveCounter : 51|4@0+ (1,0) [0|15] "" Vector__XXX
 SG_ FRS_Obj_XAccRel : 39|7@0+ (0.15,-9.6) [-9.6|9.45] "m/s2" Vector__XXX
 SG_ FRS_Obj_XVelRel_Stdev : 32|7@0+ (0.05,0) [0|6.35] "m/s" Vector__XXX
 SG_ FRS_Obj_YPos_Stdev : 22|7@0+ (0.1,0) [0|12.7] "m" Vector__XXX
 SG_ FRS_Obj_XPos_Stdev : 14|7@0+ (0.1,0) [0|12.7] "m" Vector__XXX
 SG_ FRS_ObjMotionPattern : 31|3@0+ (1,0) [0|7] "" Vector__XXX
 SG_ FRS_Obj_ValidFlag : 23|1@0+ (1,0) [0|1] "" Vector__XXX
 SG_ FRS_Obj_UpdateFlag : 15|1@0+ (1,0) [0|1] "" Vector__XXX
 SG_ FRS_Obj_ObstacleProb : 28|5@0+ (3.226,0) [0|100] "%" Vector__XXX
 SG_ Obj_ID : 7|8@0+ (1,0) [0|255] "" Vector__XXX

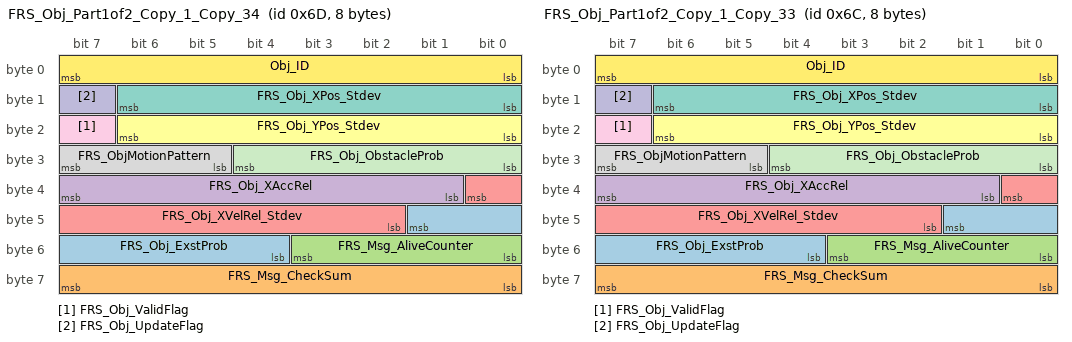
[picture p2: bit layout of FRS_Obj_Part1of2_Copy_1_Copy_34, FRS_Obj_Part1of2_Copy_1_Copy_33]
BO_ 109 FRS_Obj_Part1of2_Copy_1_Copy_34: 8 Vector__XXX
 SG_ FRS_Obj_ExstProb : 41|6@0+ (1.587,0) [0|100] "%" Vector__XXX
 SG_ FRS_Msg_CheckSum : 63|8@0+ (1,0) [0|255] "" Vector__XXX
 SG_ FRS_Msg_AliveCounter : 51|4@0+ (1,0) [0|15] "" Vector__XXX
 SG_ FRS_Obj_XAccRel : 39|7@0+ (0.15,-9.6) [-9.6|9.45] "m/s2" Vector__XXX
 SG_ FRS_Obj_XVelRel_Stdev : 32|7@0+ (0.05,0) [0|6.35] "m/s" Vector__XXX
 SG_ FRS_Obj_YPos_Stdev : 22|7@0+ (0.1,0) [0|12.7] "m" Vector__XXX
 SG_ FRS_Obj_XPos_Stdev : 14|7@0+ (0.1,0) [0|12.7] "m" Vector__XXX
 SG_ FRS_ObjMotionPattern : 31|3@0+ (1,0) [0|7] "" Vector__XXX
 SG_ FRS_Obj_ValidFlag : 23|1@0+ (1,0) [0|1] "" Vector__XXX
 SG_ FRS_Obj_UpdateFlag : 15|1@0+ (1,0) [0|1] "" Vector__XXX
 SG_ FRS_Obj_ObstacleProb : 28|5@0+ (3.226,0) [0|100] "%" Vector__XXX
 SG_ Obj_ID : 7|8@0+ (1,0) [0|255] "" Vector__XXX

BO_ 108 FRS_Obj_Part1of2_Copy_1_Copy_33: 8 Vector__XXX
 SG_ FRS_Obj_ExstProb : 41|6@0+ (1.587,0) [0|100] "%" Vector__XXX
 SG_ FRS_Msg_CheckSum : 63|8@0+ (1,0) [0|255] "" Vector__XXX
 SG_ FRS_Msg_AliveCounter : 51|4@0+ (1,0) [0|15] "" Vector__XXX
 SG_ FRS_Obj_XAccRel : 39|7@0+ (0.15,-9.6) [-9.6|9.45] "m/s2" Vector__XXX
 SG_ FRS_Obj_XVelRel_Stdev : 32|7@0+ (0.05,0) [0|6.35] "m/s" Vector__XXX
 SG_ FRS_Obj_YPos_Stdev : 22|7@0+ (0.1,0) [0|12.7] "m" Vector__XXX
 SG_ FRS_Obj_XPos_Stdev : 14|7@0+ (0.1,0) [0|12.7] "m" Vector__XXX
 SG_ FRS_ObjMotionPattern : 31|3@0+ (1,0) [0|7] "" Vector__XXX
 SG_ FRS_Obj_ValidFlag : 23|1@0+ (1,0) [0|1] "" Vector__XXX
 SG_ FRS_Obj_UpdateFlag : 15|1@0+ (1,0) [0|1] "" Vector__XXX
 SG_ FRS_Obj_ObstacleProb : 28|5@0+ (3.226,0) [0|100] "%" Vector__XXX
 SG_ Obj_ID : 7|8@0+ (1,0) [0|255] "" Vector__XXX

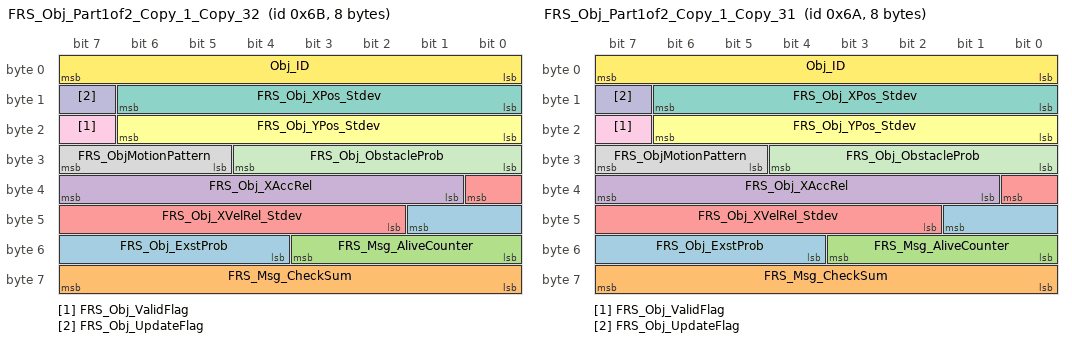
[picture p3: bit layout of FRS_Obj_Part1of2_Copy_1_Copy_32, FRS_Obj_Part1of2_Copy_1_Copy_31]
BO_ 107 FRS_Obj_Part1of2_Copy_1_Copy_32: 8 Vector__XXX
 SG_ FRS_Obj_ExstProb : 41|6@0+ (1.587,0) [0|100] "%" Vector__XXX
 SG_ FRS_Msg_CheckSum : 63|8@0+ (1,0) [0|255] "" Vector__XXX
 SG_ FRS_Msg_AliveCounter : 51|4@0+ (1,0) [0|15] "" Vector__XXX
 SG_ FRS_Obj_XAccRel : 39|7@0+ (0.15,-9.6) [-9.6|9.45] "m/s2" Vector__XXX
 SG_ FRS_Obj_XVelRel_Stdev : 32|7@0+ (0.05,0) [0|6.35] "m/s" Vector__XXX
 SG_ FRS_Obj_YPos_Stdev : 22|7@0+ (0.1,0) [0|12.7] "m" Vector__XXX
 SG_ FRS_Obj_XPos_Stdev : 14|7@0+ (0.1,0) [0|12.7] "m" Vector__XXX
 SG_ FRS_ObjMotionPattern : 31|3@0+ (1,0) [0|7] "" Vector__XXX
 SG_ FRS_Obj_ValidFlag : 23|1@0+ (1,0) [0|1] "" Vector__XXX
 SG_ FRS_Obj_UpdateFlag : 15|1@0+ (1,0) [0|1] "" Vector__XXX
 SG_ FRS_Obj_ObstacleProb : 28|5@0+ (3.226,0) [0|100] "%" Vector__XXX
 SG_ Obj_ID : 7|8@0+ (1,0) [0|255] "" Vector__XXX

BO_ 106 FRS_Obj_Part1of2_Copy_1_Copy_31: 8 Vector__XXX
 SG_ FRS_Obj_ExstProb : 41|6@0+ (1.587,0) [0|100] "%" Vector__XXX
 SG_ FRS_Msg_CheckSum : 63|8@0+ (1,0) [0|255] "" Vector__XXX
 SG_ FRS_Msg_AliveCounter : 51|4@0+ (1,0) [0|15] "" Vector__XXX
 SG_ FRS_Obj_XAccRel : 39|7@0+ (0.15,-9.6) [-9.6|9.45] "m/s2" Vector__XXX
 SG_ FRS_Obj_XVelRel_Stdev : 32|7@0+ (0.05,0) [0|6.35] "m/s" Vector__XXX
 SG_ FRS_Obj_YPos_Stdev : 22|7@0+ (0.1,0) [0|12.7] "m" Vector__XXX
 SG_ FRS_Obj_XPos_Stdev : 14|7@0+ (0.1,0) [0|12.7] "m" Vector__XXX
 SG_ FRS_ObjMotionPattern : 31|3@0+ (1,0) [0|7] "" Vector__XXX
 SG_ FRS_Obj_ValidFlag : 23|1@0+ (1,0) [0|1] "" Vector__XXX
 SG_ FRS_Obj_UpdateFlag : 15|1@0+ (1,0) [0|1] "" Vector__XXX
 SG_ FRS_Obj_ObstacleProb : 28|5@0+ (3.226,0) [0|100] "%" Vector__XXX
 SG_ Obj_ID : 7|8@0+ (1,0) [0|255] "" Vector__XXX

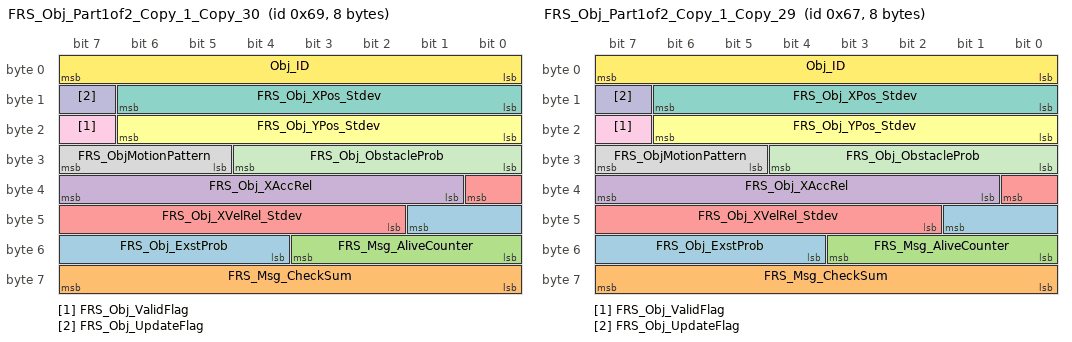
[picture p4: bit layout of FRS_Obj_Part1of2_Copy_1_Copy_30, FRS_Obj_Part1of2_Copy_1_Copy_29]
BO_ 105 FRS_Obj_Part1of2_Copy_1_Copy_30: 8 Vector__XXX
 SG_ FRS_Obj_ExstProb : 41|6@0+ (1.587,0) [0|100] "%" Vector__XXX
 SG_ FRS_Msg_CheckSum : 63|8@0+ (1,0) [0|255] "" Vector__XXX
 SG_ FRS_Msg_AliveCounter : 51|4@0+ (1,0) [0|15] "" Vector__XXX
 SG_ FRS_Obj_XAccRel : 39|7@0+ (0.15,-9.6) [-9.6|9.45] "m/s2" Vector__XXX
 SG_ FRS_Obj_XVelRel_Stdev : 32|7@0+ (0.05,0) [0|6.35] "m/s" Vector__XXX
 SG_ FRS_Obj_YPos_Stdev : 22|7@0+ (0.1,0) [0|12.7] "m" Vector__XXX
 SG_ FRS_Obj_XPos_Stdev : 14|7@0+ (0.1,0) [0|12.7] "m" Vector__XXX
 SG_ FRS_ObjMotionPattern : 31|3@0+ (1,0) [0|7] "" Vector__XXX
 SG_ FRS_Obj_ValidFlag : 23|1@0+ (1,0) [0|1] "" Vector__XXX
 SG_ FRS_Obj_UpdateFlag : 15|1@0+ (1,0) [0|1] "" Vector__XXX
 SG_ FRS_Obj_ObstacleProb : 28|5@0+ (3.226,0) [0|100] "%" Vector__XXX
 SG_ Obj_ID : 7|8@0+ (1,0) [0|255] "" Vector__XXX

BO_ 103 FRS_Obj_Part1of2_Copy_1_Copy_29: 8 Vector__XXX
 SG_ FRS_Obj_ExstProb : 41|6@0+ (1.587,0) [0|100] "%" Vector__XXX
 SG_ FRS_Msg_CheckSum : 63|8@0+ (1,0) [0|255] "" Vector__XXX
 SG_ FRS_Msg_AliveCounter : 51|4@0+ (1,0) [0|15] "" Vector__XXX
 SG_ FRS_Obj_XAccRel : 39|7@0+ (0.15,-9.6) [-9.6|9.45] "m/s2" Vector__XXX
 SG_ FRS_Obj_XVelRel_Stdev : 32|7@0+ (0.05,0) [0|6.35] "m/s" Vector__XXX
 SG_ FRS_Obj_YPos_Stdev : 22|7@0+ (0.1,0) [0|12.7] "m" Vector__XXX
 SG_ FRS_Obj_XPos_Stdev : 14|7@0+ (0.1,0) [0|12.7] "m" Vector__XXX
 SG_ FRS_ObjMotionPattern : 31|3@0+ (1,0) [0|7] "" Vector__XXX
 SG_ FRS_Obj_ValidFlag : 23|1@0+ (1,0) [0|1] "" Vector__XXX
 SG_ FRS_Obj_UpdateFlag : 15|1@0+ (1,0) [0|1] "" Vector__XXX
 SG_ FRS_Obj_ObstacleProb : 28|5@0+ (3.226,0) [0|100] "%" Vector__XXX
 SG_ Obj_ID : 7|8@0+ (1,0) [0|255] "" Vector__XXX

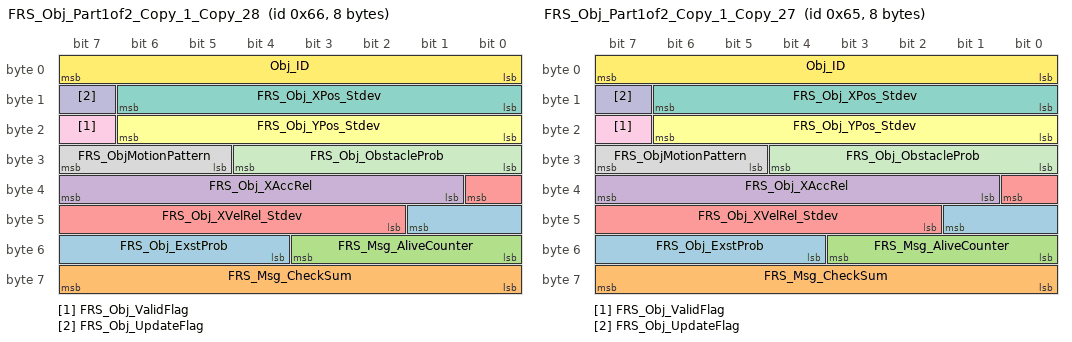
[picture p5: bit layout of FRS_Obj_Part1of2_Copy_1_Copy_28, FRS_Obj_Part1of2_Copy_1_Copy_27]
BO_ 102 FRS_Obj_Part1of2_Copy_1_Copy_28: 8 Vector__XXX
 SG_ FRS_Obj_ExstProb : 41|6@0+ (1.587,0) [0|100] "%" Vector__XXX
 SG_ FRS_Msg_CheckSum : 63|8@0+ (1,0) [0|255] "" Vector__XXX
 SG_ FRS_Msg_AliveCounter : 51|4@0+ (1,0) [0|15] "" Vector__XXX
 SG_ FRS_Obj_XAccRel : 39|7@0+ (0.15,-9.6) [-9.6|9.45] "m/s2" Vector__XXX
 SG_ FRS_Obj_XVelRel_Stdev : 32|7@0+ (0.05,0) [0|6.35] "m/s" Vector__XXX
 SG_ FRS_Obj_YPos_Stdev : 22|7@0+ (0.1,0) [0|12.7] "m" Vector__XXX
 SG_ FRS_Obj_XPos_Stdev : 14|7@0+ (0.1,0) [0|12.7] "m" Vector__XXX
 SG_ FRS_ObjMotionPattern : 31|3@0+ (1,0) [0|7] "" Vector__XXX
 SG_ FRS_Obj_ValidFlag : 23|1@0+ (1,0) [0|1] "" Vector__XXX
 SG_ FRS_Obj_UpdateFlag : 15|1@0+ (1,0) [0|1] "" Vector__XXX
 SG_ FRS_Obj_ObstacleProb : 28|5@0+ (3.226,0) [0|100] "%" Vector__XXX
 SG_ Obj_ID : 7|8@0+ (1,0) [0|255] "" Vector__XXX

BO_ 101 FRS_Obj_Part1of2_Copy_1_Copy_27: 8 Vector__XXX
 SG_ FRS_Obj_ExstProb : 41|6@0+ (1.587,0) [0|100] "%" Vector__XXX
 SG_ FRS_Msg_CheckSum : 63|8@0+ (1,0) [0|255] "" Vector__XXX
 SG_ FRS_Msg_AliveCounter : 51|4@0+ (1,0) [0|15] "" Vector__XXX
 SG_ FRS_Obj_XAccRel : 39|7@0+ (0.15,-9.6) [-9.6|9.45] "m/s2" Vector__XXX
 SG_ FRS_Obj_XVelRel_Stdev : 32|7@0+ (0.05,0) [0|6.35] "m/s" Vector__XXX
 SG_ FRS_Obj_YPos_Stdev : 22|7@0+ (0.1,0) [0|12.7] "m" Vector__XXX
 SG_ FRS_Obj_XPos_Stdev : 14|7@0+ (0.1,0) [0|12.7] "m" Vector__XXX
 SG_ FRS_ObjMotionPattern : 31|3@0+ (1,0) [0|7] "" Vector__XXX
 SG_ FRS_Obj_ValidFlag : 23|1@0+ (1,0) [0|1] "" Vector__XXX
 SG_ FRS_Obj_UpdateFlag : 15|1@0+ (1,0) [0|1] "" Vector__XXX
 SG_ FRS_Obj_ObstacleProb : 28|5@0+ (3.226,0) [0|100] "%" Vector__XXX
 SG_ Obj_ID : 7|8@0+ (1,0) [0|255] "" Vector__XXX

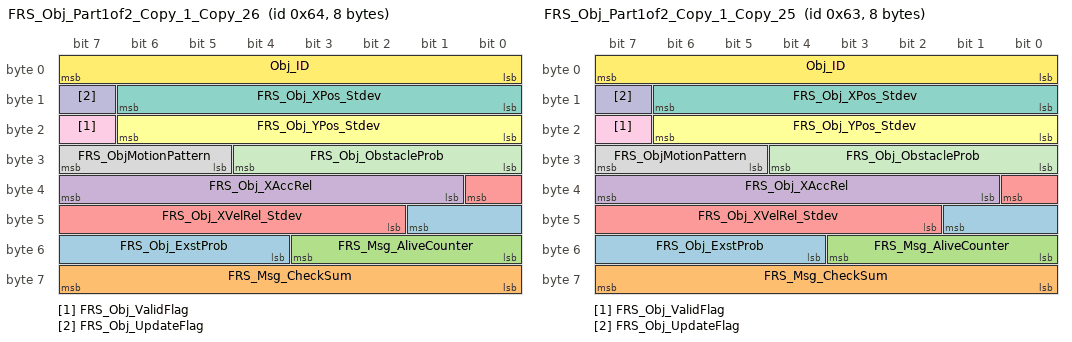
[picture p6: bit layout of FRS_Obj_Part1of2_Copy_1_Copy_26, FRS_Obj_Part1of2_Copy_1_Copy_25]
BO_ 100 FRS_Obj_Part1of2_Copy_1_Copy_26: 8 Vector__XXX
 SG_ FRS_Obj_ExstProb : 41|6@0+ (1.587,0) [0|100] "%" Vector__XXX
 SG_ FRS_Msg_CheckSum : 63|8@0+ (1,0) [0|255] "" Vector__XXX
 SG_ FRS_Msg_AliveCounter : 51|4@0+ (1,0) [0|15] "" Vector__XXX
 SG_ FRS_Obj_XAccRel : 39|7@0+ (0.15,-9.6) [-9.6|9.45] "m/s2" Vector__XXX
 SG_ FRS_Obj_XVelRel_Stdev : 32|7@0+ (0.05,0) [0|6.35] "m/s" Vector__XXX
 SG_ FRS_Obj_YPos_Stdev : 22|7@0+ (0.1,0) [0|12.7] "m" Vector__XXX
 SG_ FRS_Obj_XPos_Stdev : 14|7@0+ (0.1,0) [0|12.7] "m" Vector__XXX
 SG_ FRS_ObjMotionPattern : 31|3@0+ (1,0) [0|7] "" Vector__XXX
 SG_ FRS_Obj_ValidFlag : 23|1@0+ (1,0) [0|1] "" Vector__XXX
 SG_ FRS_Obj_UpdateFlag : 15|1@0+ (1,0) [0|1] "" Vector__XXX
 SG_ FRS_Obj_ObstacleProb : 28|5@0+ (3.226,0) [0|100] "%" Vector__XXX
 SG_ Obj_ID : 7|8@0+ (1,0) [0|255] "" Vector__XXX

BO_ 99 FRS_Obj_Part1of2_Copy_1_Copy_25: 8 Vector__XXX
 SG_ FRS_Obj_ExstProb : 41|6@0+ (1.587,0) [0|100] "%" Vector__XXX
 SG_ FRS_Msg_CheckSum : 63|8@0+ (1,0) [0|255] "" Vector__XXX
 SG_ FRS_Msg_AliveCounter : 51|4@0+ (1,0) [0|15] "" Vector__XXX
 SG_ FRS_Obj_XAccRel : 39|7@0+ (0.15,-9.6) [-9.6|9.45] "m/s2" Vector__XXX
 SG_ FRS_Obj_XVelRel_Stdev : 32|7@0+ (0.05,0) [0|6.35] "m/s" Vector__XXX
 SG_ FRS_Obj_YPos_Stdev : 22|7@0+ (0.1,0) [0|12.7] "m" Vector__XXX
 SG_ FRS_Obj_XPos_Stdev : 14|7@0+ (0.1,0) [0|12.7] "m" Vector__XXX
 SG_ FRS_ObjMotionPattern : 31|3@0+ (1,0) [0|7] "" Vector__XXX
 SG_ FRS_Obj_ValidFlag : 23|1@0+ (1,0) [0|1] "" Vector__XXX
 SG_ FRS_Obj_UpdateFlag : 15|1@0+ (1,0) [0|1] "" Vector__XXX
 SG_ FRS_Obj_ObstacleProb : 28|5@0+ (3.226,0) [0|100] "%" Vector__XXX
 SG_ Obj_ID : 7|8@0+ (1,0) [0|255] "" Vector__XXX

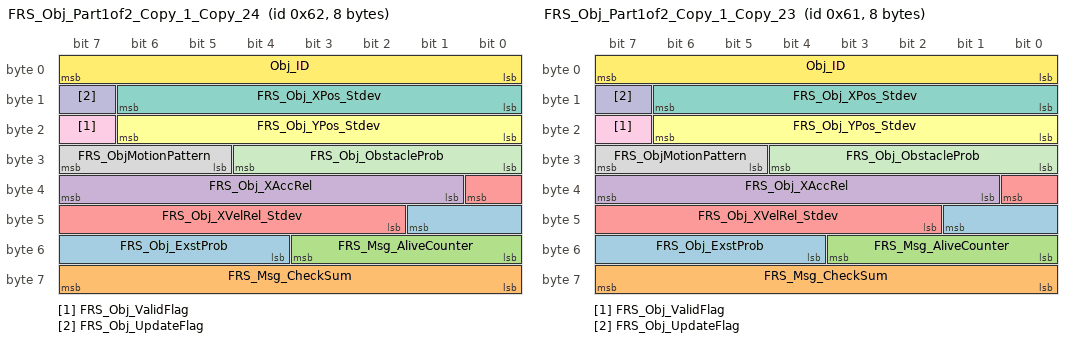
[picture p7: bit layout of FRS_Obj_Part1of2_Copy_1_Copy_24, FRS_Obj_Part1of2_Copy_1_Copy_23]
BO_ 98 FRS_Obj_Part1of2_Copy_1_Copy_24: 8 Vector__XXX
 SG_ FRS_Obj_ExstProb : 41|6@0+ (1.587,0) [0|100] "%" Vector__XXX
 SG_ FRS_Msg_CheckSum : 63|8@0+ (1,0) [0|255] "" Vector__XXX
 SG_ FRS_Msg_AliveCounter : 51|4@0+ (1,0) [0|15] "" Vector__XXX
 SG_ FRS_Obj_XAccRel : 39|7@0+ (0.15,-9.6) [-9.6|9.45] "m/s2" Vector__XXX
 SG_ FRS_Obj_XVelRel_Stdev : 32|7@0+ (0.05,0) [0|6.35] "m/s" Vector__XXX
 SG_ FRS_Obj_YPos_Stdev : 22|7@0+ (0.1,0) [0|12.7] "m" Vector__XXX
 SG_ FRS_Obj_XPos_Stdev : 14|7@0+ (0.1,0) [0|12.7] "m" Vector__XXX
 SG_ FRS_ObjMotionPattern : 31|3@0+ (1,0) [0|7] "" Vector__XXX
 SG_ FRS_Obj_ValidFlag : 23|1@0+ (1,0) [0|1] "" Vector__XXX
 SG_ FRS_Obj_UpdateFlag : 15|1@0+ (1,0) [0|1] "" Vector__XXX
 SG_ FRS_Obj_ObstacleProb : 28|5@0+ (3.226,0) [0|100] "%" Vector__XXX
 SG_ Obj_ID : 7|8@0+ (1,0) [0|255] "" Vector__XXX

BO_ 97 FRS_Obj_Part1of2_Copy_1_Copy_23: 8 Vector__XXX
 SG_ FRS_Obj_ExstProb : 41|6@0+ (1.587,0) [0|100] "%" Vector__XXX
 SG_ FRS_Msg_CheckSum : 63|8@0+ (1,0) [0|255] "" Vector__XXX
 SG_ FRS_Msg_AliveCounter : 51|4@0+ (1,0) [0|15] "" Vector__XXX
 SG_ FRS_Obj_XAccRel : 39|7@0+ (0.15,-9.6) [-9.6|9.45] "m/s2" Vector__XXX
 SG_ FRS_Obj_XVelRel_Stdev : 32|7@0+ (0.05,0) [0|6.35] "m/s" Vector__XXX
 SG_ FRS_Obj_YPos_Stdev : 22|7@0+ (0.1,0) [0|12.7] "m" Vector__XXX
 SG_ FRS_Obj_XPos_Stdev : 14|7@0+ (0.1,0) [0|12.7] "m" Vector__XXX
 SG_ FRS_ObjMotionPattern : 31|3@0+ (1,0) [0|7] "" Vector__XXX
 SG_ FRS_Obj_ValidFlag : 23|1@0+ (1,0) [0|1] "" Vector__XXX
 SG_ FRS_Obj_UpdateFlag : 15|1@0+ (1,0) [0|1] "" Vector__XXX
 SG_ FRS_Obj_ObstacleProb : 28|5@0+ (3.226,0) [0|100] "%" Vector__XXX
 SG_ Obj_ID : 7|8@0+ (1,0) [0|255] "" Vector__XXX

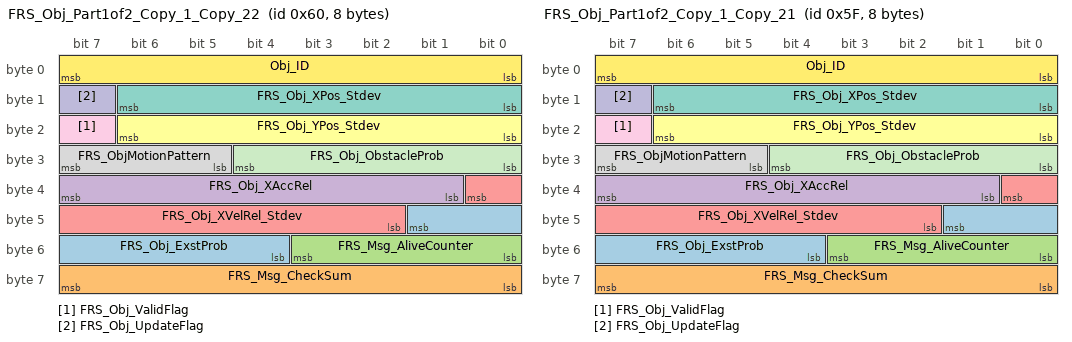
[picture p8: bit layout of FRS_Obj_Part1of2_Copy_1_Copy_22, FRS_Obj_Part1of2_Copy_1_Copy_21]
BO_ 96 FRS_Obj_Part1of2_Copy_1_Copy_22: 8 Vector__XXX
 SG_ FRS_Obj_ExstProb : 41|6@0+ (1.587,0) [0|100] "%" Vector__XXX
 SG_ FRS_Msg_CheckSum : 63|8@0+ (1,0) [0|255] "" Vector__XXX
 SG_ FRS_Msg_AliveCounter : 51|4@0+ (1,0) [0|15] "" Vector__XXX
 SG_ FRS_Obj_XAccRel : 39|7@0+ (0.15,-9.6) [-9.6|9.45] "m/s2" Vector__XXX
 SG_ FRS_Obj_XVelRel_Stdev : 32|7@0+ (0.05,0) [0|6.35] "m/s" Vector__XXX
 SG_ FRS_Obj_YPos_Stdev : 22|7@0+ (0.1,0) [0|12.7] "m" Vector__XXX
 SG_ FRS_Obj_XPos_Stdev : 14|7@0+ (0.1,0) [0|12.7] "m" Vector__XXX
 SG_ FRS_ObjMotionPattern : 31|3@0+ (1,0) [0|7] "" Vector__XXX
 SG_ FRS_Obj_ValidFlag : 23|1@0+ (1,0) [0|1] "" Vector__XXX
 SG_ FRS_Obj_UpdateFlag : 15|1@0+ (1,0) [0|1] "" Vector__XXX
 SG_ FRS_Obj_ObstacleProb : 28|5@0+ (3.226,0) [0|100] "%" Vector__XXX
 SG_ Obj_ID : 7|8@0+ (1,0) [0|255] "" Vector__XXX

BO_ 95 FRS_Obj_Part1of2_Copy_1_Copy_21: 8 Vector__XXX
 SG_ FRS_Obj_ExstProb : 41|6@0+ (1.587,0) [0|100] "%" Vector__XXX
 SG_ FRS_Msg_CheckSum : 63|8@0+ (1,0) [0|255] "" Vector__XXX
 SG_ FRS_Msg_AliveCounter : 51|4@0+ (1,0) [0|15] "" Vector__XXX
 SG_ FRS_Obj_XAccRel : 39|7@0+ (0.15,-9.6) [-9.6|9.45] "m/s2" Vector__XXX
 SG_ FRS_Obj_XVelRel_Stdev : 32|7@0+ (0.05,0) [0|6.35] "m/s" Vector__XXX
 SG_ FRS_Obj_YPos_Stdev : 22|7@0+ (0.1,0) [0|12.7] "m" Vector__XXX
 SG_ FRS_Obj_XPos_Stdev : 14|7@0+ (0.1,0) [0|12.7] "m" Vector__XXX
 SG_ FRS_ObjMotionPattern : 31|3@0+ (1,0) [0|7] "" Vector__XXX
 SG_ FRS_Obj_ValidFlag : 23|1@0+ (1,0) [0|1] "" Vector__XXX
 SG_ FRS_Obj_UpdateFlag : 15|1@0+ (1,0) [0|1] "" Vector__XXX
 SG_ FRS_Obj_ObstacleProb : 28|5@0+ (3.226,0) [0|100] "%" Vector__XXX
 SG_ Obj_ID : 7|8@0+ (1,0) [0|255] "" Vector__XXX

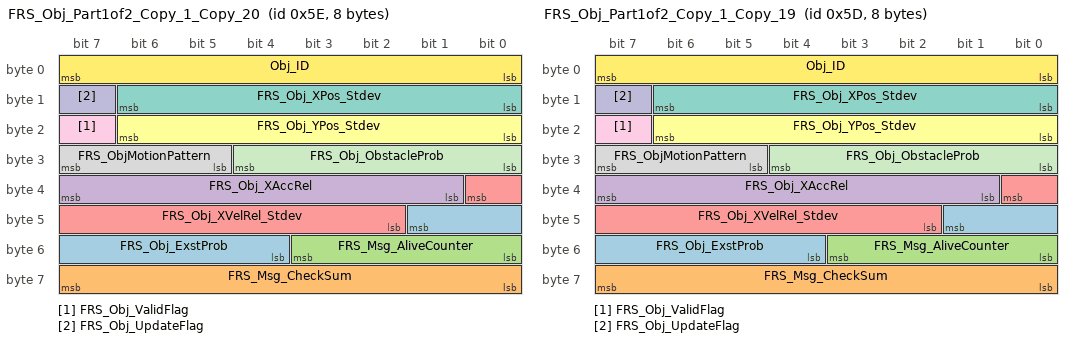
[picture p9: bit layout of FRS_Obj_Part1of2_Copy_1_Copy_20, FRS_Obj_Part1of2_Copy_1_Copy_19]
BO_ 94 FRS_Obj_Part1of2_Copy_1_Copy_20: 8 Vector__XXX
 SG_ FRS_Obj_ExstProb : 41|6@0+ (1.587,0) [0|100] "%" Vector__XXX
 SG_ FRS_Msg_CheckSum : 63|8@0+ (1,0) [0|255] "" Vector__XXX
 SG_ FRS_Msg_AliveCounter : 51|4@0+ (1,0) [0|15] "" Vector__XXX
 SG_ FRS_Obj_XAccRel : 39|7@0+ (0.15,-9.6) [-9.6|9.45] "m/s2" Vector__XXX
 SG_ FRS_Obj_XVelRel_Stdev : 32|7@0+ (0.05,0) [0|6.35] "m/s" Vector__XXX
 SG_ FRS_Obj_YPos_Stdev : 22|7@0+ (0.1,0) [0|12.7] "m" Vector__XXX
 SG_ FRS_Obj_XPos_Stdev : 14|7@0+ (0.1,0) [0|12.7] "m" Vector__XXX
 SG_ FRS_ObjMotionPattern : 31|3@0+ (1,0) [0|7] "" Vector__XXX
 SG_ FRS_Obj_ValidFlag : 23|1@0+ (1,0) [0|1] "" Vector__XXX
 SG_ FRS_Obj_UpdateFlag : 15|1@0+ (1,0) [0|1] "" Vector__XXX
 SG_ FRS_Obj_ObstacleProb : 28|5@0+ (3.226,0) [0|100] "%" Vector__XXX
 SG_ Obj_ID : 7|8@0+ (1,0) [0|255] "" Vector__XXX

BO_ 93 FRS_Obj_Part1of2_Copy_1_Copy_19: 8 Vector__XXX
 SG_ FRS_Obj_ExstProb : 41|6@0+ (1.587,0) [0|100] "%" Vector__XXX
 SG_ FRS_Msg_CheckSum : 63|8@0+ (1,0) [0|255] "" Vector__XXX
 SG_ FRS_Msg_AliveCounter : 51|4@0+ (1,0) [0|15] "" Vector__XXX
 SG_ FRS_Obj_XAccRel : 39|7@0+ (0.15,-9.6) [-9.6|9.45] "m/s2" Vector__XXX
 SG_ FRS_Obj_XVelRel_Stdev : 32|7@0+ (0.05,0) [0|6.35] "m/s" Vector__XXX
 SG_ FRS_Obj_YPos_Stdev : 22|7@0+ (0.1,0) [0|12.7] "m" Vector__XXX
 SG_ FRS_Obj_XPos_Stdev : 14|7@0+ (0.1,0) [0|12.7] "m" Vector__XXX
 SG_ FRS_ObjMotionPattern : 31|3@0+ (1,0) [0|7] "" Vector__XXX
 SG_ FRS_Obj_ValidFlag : 23|1@0+ (1,0) [0|1] "" Vector__XXX
 SG_ FRS_Obj_UpdateFlag : 15|1@0+ (1,0) [0|1] "" Vector__XXX
 SG_ FRS_Obj_ObstacleProb : 28|5@0+ (3.226,0) [0|100] "%" Vector__XXX
 SG_ Obj_ID : 7|8@0+ (1,0) [0|255] "" Vector__XXX

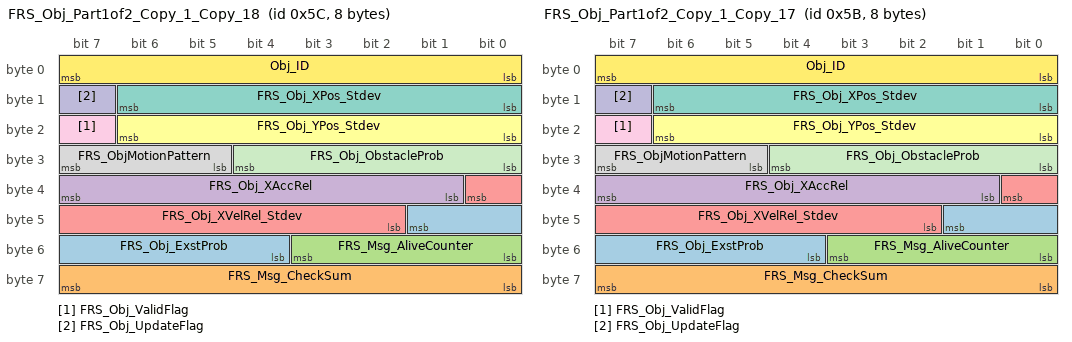
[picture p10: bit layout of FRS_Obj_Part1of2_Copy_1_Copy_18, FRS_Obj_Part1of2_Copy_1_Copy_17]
BO_ 92 FRS_Obj_Part1of2_Copy_1_Copy_18: 8 Vector__XXX
 SG_ FRS_Obj_ExstProb : 41|6@0+ (1.587,0) [0|100] "%" Vector__XXX
 SG_ FRS_Msg_CheckSum : 63|8@0+ (1,0) [0|255] "" Vector__XXX
 SG_ FRS_Msg_AliveCounter : 51|4@0+ (1,0) [0|15] "" Vector__XXX
 SG_ FRS_Obj_XAccRel : 39|7@0+ (0.15,-9.6) [-9.6|9.45] "m/s2" Vector__XXX
 SG_ FRS_Obj_XVelRel_Stdev : 32|7@0+ (0.05,0) [0|6.35] "m/s" Vector__XXX
 SG_ FRS_Obj_YPos_Stdev : 22|7@0+ (0.1,0) [0|12.7] "m" Vector__XXX
 SG_ FRS_Obj_XPos_Stdev : 14|7@0+ (0.1,0) [0|12.7] "m" Vector__XXX
 SG_ FRS_ObjMotionPattern : 31|3@0+ (1,0) [0|7] "" Vector__XXX
 SG_ FRS_Obj_ValidFlag : 23|1@0+ (1,0) [0|1] "" Vector__XXX
 SG_ FRS_Obj_UpdateFlag : 15|1@0+ (1,0) [0|1] "" Vector__XXX
 SG_ FRS_Obj_ObstacleProb : 28|5@0+ (3.226,0) [0|100] "%" Vector__XXX
 SG_ Obj_ID : 7|8@0+ (1,0) [0|255] "" Vector__XXX

BO_ 91 FRS_Obj_Part1of2_Copy_1_Copy_17: 8 Vector__XXX
 SG_ FRS_Obj_ExstProb : 41|6@0+ (1.587,0) [0|100] "%" Vector__XXX
 SG_ FRS_Msg_CheckSum : 63|8@0+ (1,0) [0|255] "" Vector__XXX
 SG_ FRS_Msg_AliveCounter : 51|4@0+ (1,0) [0|15] "" Vector__XXX
 SG_ FRS_Obj_XAccRel : 39|7@0+ (0.15,-9.6) [-9.6|9.45] "m/s2" Vector__XXX
 SG_ FRS_Obj_XVelRel_Stdev : 32|7@0+ (0.05,0) [0|6.35] "m/s" Vector__XXX
 SG_ FRS_Obj_YPos_Stdev : 22|7@0+ (0.1,0) [0|12.7] "m" Vector__XXX
 SG_ FRS_Obj_XPos_Stdev : 14|7@0+ (0.1,0) [0|12.7] "m" Vector__XXX
 SG_ FRS_ObjMotionPattern : 31|3@0+ (1,0) [0|7] "" Vector__XXX
 SG_ FRS_Obj_ValidFlag : 23|1@0+ (1,0) [0|1] "" Vector__XXX
 SG_ FRS_Obj_UpdateFlag : 15|1@0+ (1,0) [0|1] "" Vector__XXX
 SG_ FRS_Obj_ObstacleProb : 28|5@0+ (3.226,0) [0|100] "%" Vector__XXX
 SG_ Obj_ID : 7|8@0+ (1,0) [0|255] "" Vector__XXX

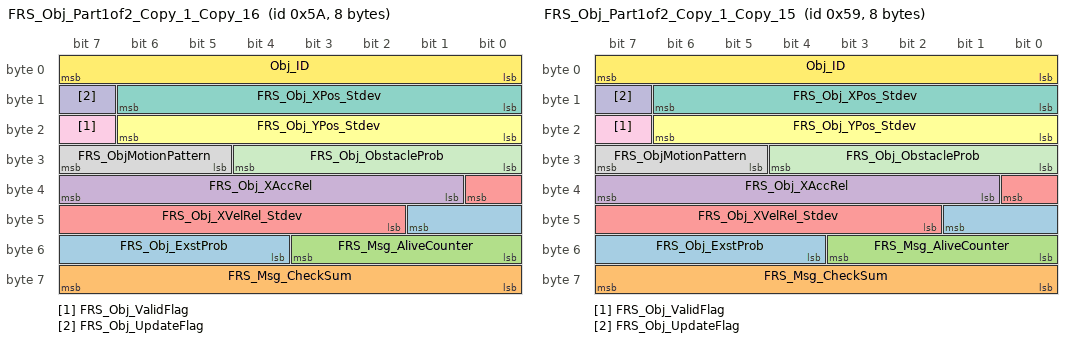
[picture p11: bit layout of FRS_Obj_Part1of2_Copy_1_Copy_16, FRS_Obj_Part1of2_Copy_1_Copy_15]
BO_ 90 FRS_Obj_Part1of2_Copy_1_Copy_16: 8 Vector__XXX
 SG_ FRS_Obj_ExstProb : 41|6@0+ (1.587,0) [0|100] "%" Vector__XXX
 SG_ FRS_Msg_CheckSum : 63|8@0+ (1,0) [0|255] "" Vector__XXX
 SG_ FRS_Msg_AliveCounter : 51|4@0+ (1,0) [0|15] "" Vector__XXX
 SG_ FRS_Obj_XAccRel : 39|7@0+ (0.15,-9.6) [-9.6|9.45] "m/s2" Vector__XXX
 SG_ FRS_Obj_XVelRel_Stdev : 32|7@0+ (0.05,0) [0|6.35] "m/s" Vector__XXX
 SG_ FRS_Obj_YPos_Stdev : 22|7@0+ (0.1,0) [0|12.7] "m" Vector__XXX
 SG_ FRS_Obj_XPos_Stdev : 14|7@0+ (0.1,0) [0|12.7] "m" Vector__XXX
 SG_ FRS_ObjMotionPattern : 31|3@0+ (1,0) [0|7] "" Vector__XXX
 SG_ FRS_Obj_ValidFlag : 23|1@0+ (1,0) [0|1] "" Vector__XXX
 SG_ FRS_Obj_UpdateFlag : 15|1@0+ (1,0) [0|1] "" Vector__XXX
 SG_ FRS_Obj_ObstacleProb : 28|5@0+ (3.226,0) [0|100] "%" Vector__XXX
 SG_ Obj_ID : 7|8@0+ (1,0) [0|255] "" Vector__XXX

BO_ 89 FRS_Obj_Part1of2_Copy_1_Copy_15: 8 Vector__XXX
 SG_ FRS_Obj_ExstProb : 41|6@0+ (1.587,0) [0|100] "%" Vector__XXX
 SG_ FRS_Msg_CheckSum : 63|8@0+ (1,0) [0|255] "" Vector__XXX
 SG_ FRS_Msg_AliveCounter : 51|4@0+ (1,0) [0|15] "" Vector__XXX
 SG_ FRS_Obj_XAccRel : 39|7@0+ (0.15,-9.6) [-9.6|9.45] "m/s2" Vector__XXX
 SG_ FRS_Obj_XVelRel_Stdev : 32|7@0+ (0.05,0) [0|6.35] "m/s" Vector__XXX
 SG_ FRS_Obj_YPos_Stdev : 22|7@0+ (0.1,0) [0|12.7] "m" Vector__XXX
 SG_ FRS_Obj_XPos_Stdev : 14|7@0+ (0.1,0) [0|12.7] "m" Vector__XXX
 SG_ FRS_ObjMotionPattern : 31|3@0+ (1,0) [0|7] "" Vector__XXX
 SG_ FRS_Obj_ValidFlag : 23|1@0+ (1,0) [0|1] "" Vector__XXX
 SG_ FRS_Obj_UpdateFlag : 15|1@0+ (1,0) [0|1] "" Vector__XXX
 SG_ FRS_Obj_ObstacleProb : 28|5@0+ (3.226,0) [0|100] "%" Vector__XXX
 SG_ Obj_ID : 7|8@0+ (1,0) [0|255] "" Vector__XXX

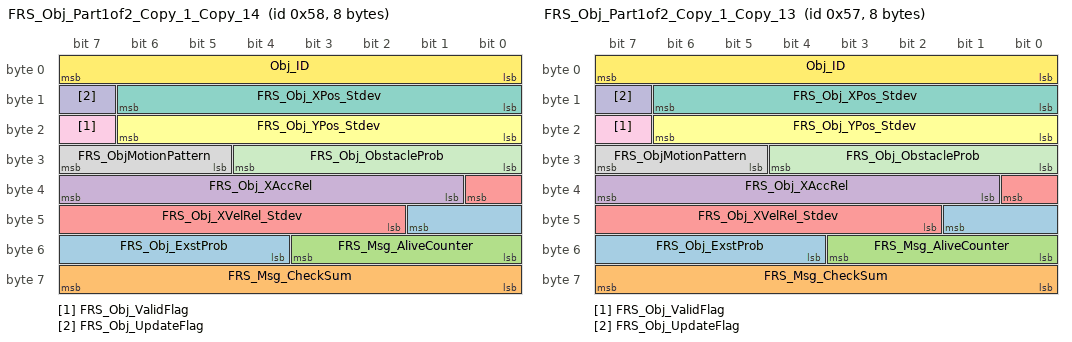
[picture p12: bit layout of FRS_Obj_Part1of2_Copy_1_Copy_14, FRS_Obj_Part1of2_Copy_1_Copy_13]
BO_ 88 FRS_Obj_Part1of2_Copy_1_Copy_14: 8 Vector__XXX
 SG_ FRS_Obj_ExstProb : 41|6@0+ (1.587,0) [0|100] "%" Vector__XXX
 SG_ FRS_Msg_CheckSum : 63|8@0+ (1,0) [0|255] "" Vector__XXX
 SG_ FRS_Msg_AliveCounter : 51|4@0+ (1,0) [0|15] "" Vector__XXX
 SG_ FRS_Obj_XAccRel : 39|7@0+ (0.15,-9.6) [-9.6|9.45] "m/s2" Vector__XXX
 SG_ FRS_Obj_XVelRel_Stdev : 32|7@0+ (0.05,0) [0|6.35] "m/s" Vector__XXX
 SG_ FRS_Obj_YPos_Stdev : 22|7@0+ (0.1,0) [0|12.7] "m" Vector__XXX
 SG_ FRS_Obj_XPos_Stdev : 14|7@0+ (0.1,0) [0|12.7] "m" Vector__XXX
 SG_ FRS_ObjMotionPattern : 31|3@0+ (1,0) [0|7] "" Vector__XXX
 SG_ FRS_Obj_ValidFlag : 23|1@0+ (1,0) [0|1] "" Vector__XXX
 SG_ FRS_Obj_UpdateFlag : 15|1@0+ (1,0) [0|1] "" Vector__XXX
 SG_ FRS_Obj_ObstacleProb : 28|5@0+ (3.226,0) [0|100] "%" Vector__XXX
 SG_ Obj_ID : 7|8@0+ (1,0) [0|255] "" Vector__XXX

BO_ 87 FRS_Obj_Part1of2_Copy_1_Copy_13: 8 Vector__XXX
 SG_ FRS_Obj_ExstProb : 41|6@0+ (1.587,0) [0|100] "%" Vector__XXX
 SG_ FRS_Msg_CheckSum : 63|8@0+ (1,0) [0|255] "" Vector__XXX
 SG_ FRS_Msg_AliveCounter : 51|4@0+ (1,0) [0|15] "" Vector__XXX
 SG_ FRS_Obj_XAccRel : 39|7@0+ (0.15,-9.6) [-9.6|9.45] "m/s2" Vector__XXX
 SG_ FRS_Obj_XVelRel_Stdev : 32|7@0+ (0.05,0) [0|6.35] "m/s" Vector__XXX
 SG_ FRS_Obj_YPos_Stdev : 22|7@0+ (0.1,0) [0|12.7] "m" Vector__XXX
 SG_ FRS_Obj_XPos_Stdev : 14|7@0+ (0.1,0) [0|12.7] "m" Vector__XXX
 SG_ FRS_ObjMotionPattern : 31|3@0+ (1,0) [0|7] "" Vector__XXX
 SG_ FRS_Obj_ValidFlag : 23|1@0+ (1,0) [0|1] "" Vector__XXX
 SG_ FRS_Obj_UpdateFlag : 15|1@0+ (1,0) [0|1] "" Vector__XXX
 SG_ FRS_Obj_ObstacleProb : 28|5@0+ (3.226,0) [0|100] "%" Vector__XXX
 SG_ Obj_ID : 7|8@0+ (1,0) [0|255] "" Vector__XXX

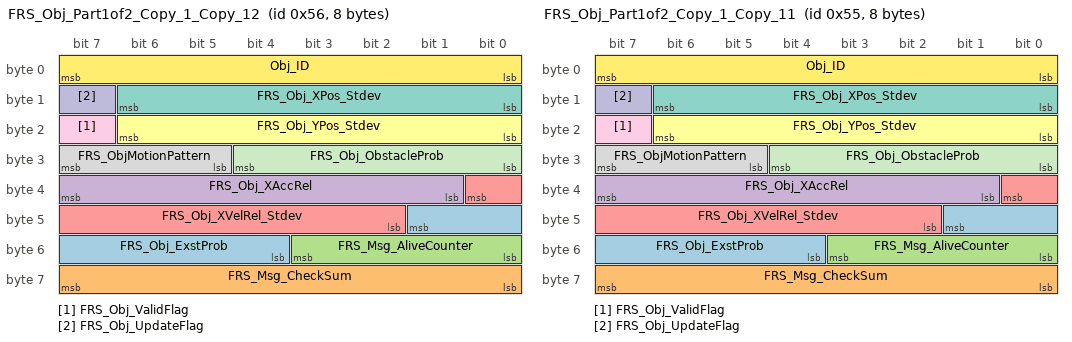
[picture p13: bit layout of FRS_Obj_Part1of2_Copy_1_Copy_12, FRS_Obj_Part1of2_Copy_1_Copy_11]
BO_ 86 FRS_Obj_Part1of2_Copy_1_Copy_12: 8 Vector__XXX
 SG_ FRS_Obj_ExstProb : 41|6@0+ (1.587,0) [0|100] "%" Vector__XXX
 SG_ FRS_Msg_CheckSum : 63|8@0+ (1,0) [0|255] "" Vector__XXX
 SG_ FRS_Msg_AliveCounter : 51|4@0+ (1,0) [0|15] "" Vector__XXX
 SG_ FRS_Obj_XAccRel : 39|7@0+ (0.15,-9.6) [-9.6|9.45] "m/s2" Vector__XXX
 SG_ FRS_Obj_XVelRel_Stdev : 32|7@0+ (0.05,0) [0|6.35] "m/s" Vector__XXX
 SG_ FRS_Obj_YPos_Stdev : 22|7@0+ (0.1,0) [0|12.7] "m" Vector__XXX
 SG_ FRS_Obj_XPos_Stdev : 14|7@0+ (0.1,0) [0|12.7] "m" Vector__XXX
 SG_ FRS_ObjMotionPattern : 31|3@0+ (1,0) [0|7] "" Vector__XXX
 SG_ FRS_Obj_ValidFlag : 23|1@0+ (1,0) [0|1] "" Vector__XXX
 SG_ FRS_Obj_UpdateFlag : 15|1@0+ (1,0) [0|1] "" Vector__XXX
 SG_ FRS_Obj_ObstacleProb : 28|5@0+ (3.226,0) [0|100] "%" Vector__XXX
 SG_ Obj_ID : 7|8@0+ (1,0) [0|255] "" Vector__XXX

BO_ 85 FRS_Obj_Part1of2_Copy_1_Copy_11: 8 Vector__XXX
 SG_ FRS_Obj_ExstProb : 41|6@0+ (1.587,0) [0|100] "%" Vector__XXX
 SG_ FRS_Msg_CheckSum : 63|8@0+ (1,0) [0|255] "" Vector__XXX
 SG_ FRS_Msg_AliveCounter : 51|4@0+ (1,0) [0|15] "" Vector__XXX
 SG_ FRS_Obj_XAccRel : 39|7@0+ (0.15,-9.6) [-9.6|9.45] "m/s2" Vector__XXX
 SG_ FRS_Obj_XVelRel_Stdev : 32|7@0+ (0.05,0) [0|6.35] "m/s" Vector__XXX
 SG_ FRS_Obj_YPos_Stdev : 22|7@0+ (0.1,0) [0|12.7] "m" Vector__XXX
 SG_ FRS_Obj_XPos_Stdev : 14|7@0+ (0.1,0) [0|12.7] "m" Vector__XXX
 SG_ FRS_ObjMotionPattern : 31|3@0+ (1,0) [0|7] "" Vector__XXX
 SG_ FRS_Obj_ValidFlag : 23|1@0+ (1,0) [0|1] "" Vector__XXX
 SG_ FRS_Obj_UpdateFlag : 15|1@0+ (1,0) [0|1] "" Vector__XXX
 SG_ FRS_Obj_ObstacleProb : 28|5@0+ (3.226,0) [0|100] "%" Vector__XXX
 SG_ Obj_ID : 7|8@0+ (1,0) [0|255] "" Vector__XXX

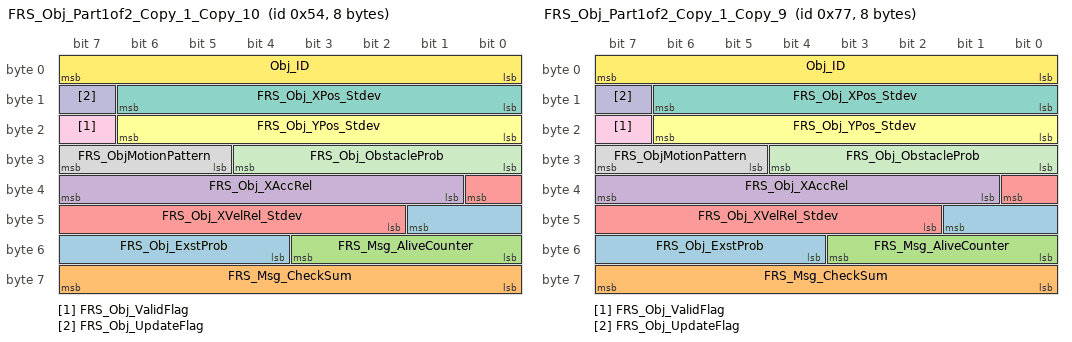
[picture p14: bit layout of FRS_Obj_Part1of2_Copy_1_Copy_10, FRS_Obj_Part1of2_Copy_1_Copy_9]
BO_ 84 FRS_Obj_Part1of2_Copy_1_Copy_10: 8 Vector__XXX
 SG_ FRS_Obj_ExstProb : 41|6@0+ (1.587,0) [0|100] "%" Vector__XXX
 SG_ FRS_Msg_CheckSum : 63|8@0+ (1,0) [0|255] "" Vector__XXX
 SG_ FRS_Msg_AliveCounter : 51|4@0+ (1,0) [0|15] "" Vector__XXX
 SG_ FRS_Obj_XAccRel : 39|7@0+ (0.15,-9.6) [-9.6|9.45] "m/s2" Vector__XXX
 SG_ FRS_Obj_XVelRel_Stdev : 32|7@0+ (0.05,0) [0|6.35] "m/s" Vector__XXX
 SG_ FRS_Obj_YPos_Stdev : 22|7@0+ (0.1,0) [0|12.7] "m" Vector__XXX
 SG_ FRS_Obj_XPos_Stdev : 14|7@0+ (0.1,0) [0|12.7] "m" Vector__XXX
 SG_ FRS_ObjMotionPattern : 31|3@0+ (1,0) [0|7] "" Vector__XXX
 SG_ FRS_Obj_ValidFlag : 23|1@0+ (1,0) [0|1] "" Vector__XXX
 SG_ FRS_Obj_UpdateFlag : 15|1@0+ (1,0) [0|1] "" Vector__XXX
 SG_ FRS_Obj_ObstacleProb : 28|5@0+ (3.226,0) [0|100] "%" Vector__XXX
 SG_ Obj_ID : 7|8@0+ (1,0) [0|255] "" Vector__XXX

BO_ 119 FRS_Obj_Part1of2_Copy_1_Copy_9: 8 Vector__XXX
 SG_ FRS_Obj_ExstProb : 41|6@0+ (1.587,0) [0|100] "%" Vector__XXX
 SG_ FRS_Msg_CheckSum : 63|8@0+ (1,0) [0|255] "" Vector__XXX
 SG_ FRS_Msg_AliveCounter : 51|4@0+ (1,0) [0|15] "" Vector__XXX
 SG_ FRS_Obj_XAccRel : 39|7@0+ (0.15,-9.6) [-9.6|9.45] "m/s2" Vector__XXX
 SG_ FRS_Obj_XVelRel_Stdev : 32|7@0+ (0.05,0) [0|6.35] "m/s" Vector__XXX
 SG_ FRS_Obj_YPos_Stdev : 22|7@0+ (0.1,0) [0|12.7] "m" Vector__XXX
 SG_ FRS_Obj_XPos_Stdev : 14|7@0+ (0.1,0) [0|12.7] "m" Vector__XXX
 SG_ FRS_ObjMotionPattern : 31|3@0+ (1,0) [0|7] "" Vector__XXX
 SG_ FRS_Obj_ValidFlag : 23|1@0+ (1,0) [0|1] "" Vector__XXX
 SG_ FRS_Obj_UpdateFlag : 15|1@0+ (1,0) [0|1] "" Vector__XXX
 SG_ FRS_Obj_ObstacleProb : 28|5@0+ (3.226,0) [0|100] "%" Vector__XXX
 SG_ Obj_ID : 7|8@0+ (1,0) [0|255] "" Vector__XXX

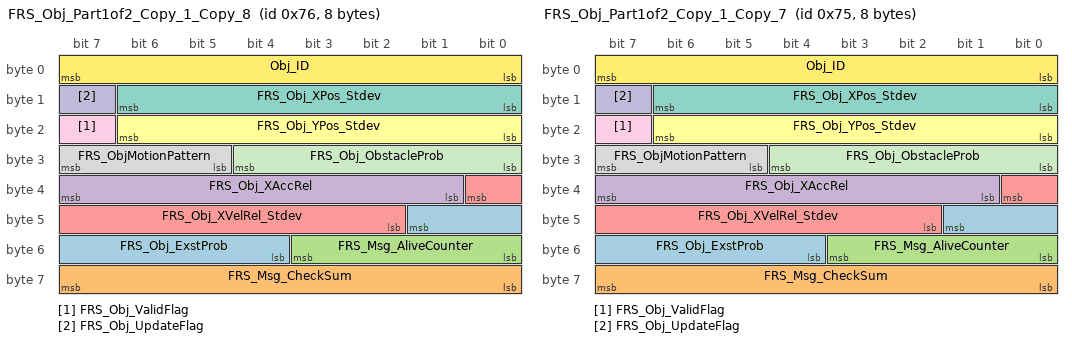
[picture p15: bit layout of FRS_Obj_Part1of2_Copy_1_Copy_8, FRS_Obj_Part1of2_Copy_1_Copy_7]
BO_ 118 FRS_Obj_Part1of2_Copy_1_Copy_8: 8 Vector__XXX
 SG_ FRS_Obj_ExstProb : 41|6@0+ (1.587,0) [0|100] "%" Vector__XXX
 SG_ FRS_Msg_CheckSum : 63|8@0+ (1,0) [0|255] "" Vector__XXX
 SG_ FRS_Msg_AliveCounter : 51|4@0+ (1,0) [0|15] "" Vector__XXX
 SG_ FRS_Obj_XAccRel : 39|7@0+ (0.15,-9.6) [-9.6|9.45] "m/s2" Vector__XXX
 SG_ FRS_Obj_XVelRel_Stdev : 32|7@0+ (0.05,0) [0|6.35] "m/s" Vector__XXX
 SG_ FRS_Obj_YPos_Stdev : 22|7@0+ (0.1,0) [0|12.7] "m" Vector__XXX
 SG_ FRS_Obj_XPos_Stdev : 14|7@0+ (0.1,0) [0|12.7] "m" Vector__XXX
 SG_ FRS_ObjMotionPattern : 31|3@0+ (1,0) [0|7] "" Vector__XXX
 SG_ FRS_Obj_ValidFlag : 23|1@0+ (1,0) [0|1] "" Vector__XXX
 SG_ FRS_Obj_UpdateFlag : 15|1@0+ (1,0) [0|1] "" Vector__XXX
 SG_ FRS_Obj_ObstacleProb : 28|5@0+ (3.226,0) [0|100] "%" Vector__XXX
 SG_ Obj_ID : 7|8@0+ (1,0) [0|255] "" Vector__XXX

BO_ 117 FRS_Obj_Part1of2_Copy_1_Copy_7: 8 Vector__XXX
 SG_ FRS_Obj_ExstProb : 41|6@0+ (1.587,0) [0|100] "%" Vector__XXX
 SG_ FRS_Msg_CheckSum : 63|8@0+ (1,0) [0|255] "" Vector__XXX
 SG_ FRS_Msg_AliveCounter : 51|4@0+ (1,0) [0|15] "" Vector__XXX
 SG_ FRS_Obj_XAccRel : 39|7@0+ (0.15,-9.6) [-9.6|9.45] "m/s2" Vector__XXX
 SG_ FRS_Obj_XVelRel_Stdev : 32|7@0+ (0.05,0) [0|6.35] "m/s" Vector__XXX
 SG_ FRS_Obj_YPos_Stdev : 22|7@0+ (0.1,0) [0|12.7] "m" Vector__XXX
 SG_ FRS_Obj_XPos_Stdev : 14|7@0+ (0.1,0) [0|12.7] "m" Vector__XXX
 SG_ FRS_ObjMotionPattern : 31|3@0+ (1,0) [0|7] "" Vector__XXX
 SG_ FRS_Obj_ValidFlag : 23|1@0+ (1,0) [0|1] "" Vector__XXX
 SG_ FRS_Obj_UpdateFlag : 15|1@0+ (1,0) [0|1] "" Vector__XXX
 SG_ FRS_Obj_ObstacleProb : 28|5@0+ (3.226,0) [0|100] "%" Vector__XXX
 SG_ Obj_ID : 7|8@0+ (1,0) [0|255] "" Vector__XXX

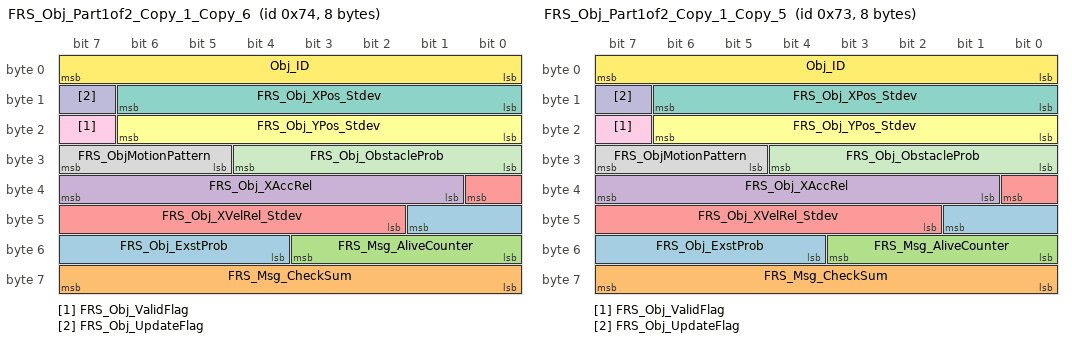
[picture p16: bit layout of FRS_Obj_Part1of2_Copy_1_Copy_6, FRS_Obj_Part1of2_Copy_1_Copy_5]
BO_ 116 FRS_Obj_Part1of2_Copy_1_Copy_6: 8 Vector__XXX
 SG_ FRS_Obj_ExstProb : 41|6@0+ (1.587,0) [0|100] "%" Vector__XXX
 SG_ FRS_Msg_CheckSum : 63|8@0+ (1,0) [0|255] "" Vector__XXX
 SG_ FRS_Msg_AliveCounter : 51|4@0+ (1,0) [0|15] "" Vector__XXX
 SG_ FRS_Obj_XAccRel : 39|7@0+ (0.15,-9.6) [-9.6|9.45] "m/s2" Vector__XXX
 SG_ FRS_Obj_XVelRel_Stdev : 32|7@0+ (0.05,0) [0|6.35] "m/s" Vector__XXX
 SG_ FRS_Obj_YPos_Stdev : 22|7@0+ (0.1,0) [0|12.7] "m" Vector__XXX
 SG_ FRS_Obj_XPos_Stdev : 14|7@0+ (0.1,0) [0|12.7] "m" Vector__XXX
 SG_ FRS_ObjMotionPattern : 31|3@0+ (1,0) [0|7] "" Vector__XXX
 SG_ FRS_Obj_ValidFlag : 23|1@0+ (1,0) [0|1] "" Vector__XXX
 SG_ FRS_Obj_UpdateFlag : 15|1@0+ (1,0) [0|1] "" Vector__XXX
 SG_ FRS_Obj_ObstacleProb : 28|5@0+ (3.226,0) [0|100] "%" Vector__XXX
 SG_ Obj_ID : 7|8@0+ (1,0) [0|255] "" Vector__XXX

BO_ 115 FRS_Obj_Part1of2_Copy_1_Copy_5: 8 Vector__XXX
 SG_ FRS_Obj_ExstProb : 41|6@0+ (1.587,0) [0|100] "%" Vector__XXX
 SG_ FRS_Msg_CheckSum : 63|8@0+ (1,0) [0|255] "" Vector__XXX
 SG_ FRS_Msg_AliveCounter : 51|4@0+ (1,0) [0|15] "" Vector__XXX
 SG_ FRS_Obj_XAccRel : 39|7@0+ (0.15,-9.6) [-9.6|9.45] "m/s2" Vector__XXX
 SG_ FRS_Obj_XVelRel_Stdev : 32|7@0+ (0.05,0) [0|6.35] "m/s" Vector__XXX
 SG_ FRS_Obj_YPos_Stdev : 22|7@0+ (0.1,0) [0|12.7] "m" Vector__XXX
 SG_ FRS_Obj_XPos_Stdev : 14|7@0+ (0.1,0) [0|12.7] "m" Vector__XXX
 SG_ FRS_ObjMotionPattern : 31|3@0+ (1,0) [0|7] "" Vector__XXX
 SG_ FRS_Obj_ValidFlag : 23|1@0+ (1,0) [0|1] "" Vector__XXX
 SG_ FRS_Obj_UpdateFlag : 15|1@0+ (1,0) [0|1] "" Vector__XXX
 SG_ FRS_Obj_ObstacleProb : 28|5@0+ (3.226,0) [0|100] "%" Vector__XXX
 SG_ Obj_ID : 7|8@0+ (1,0) [0|255] "" Vector__XXX

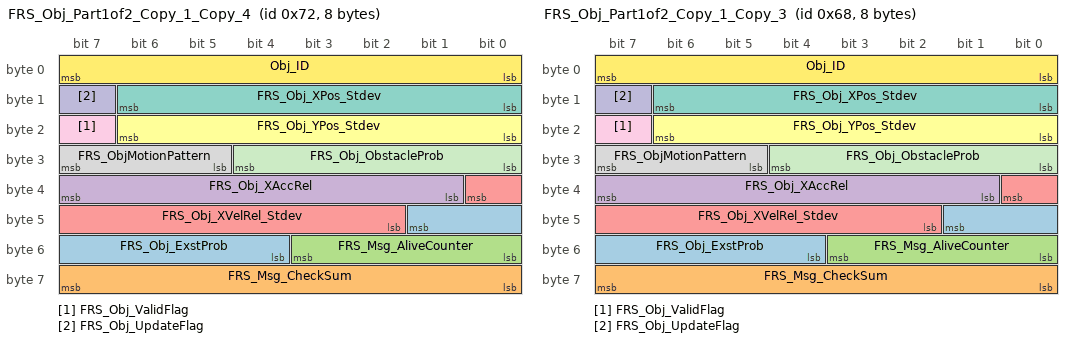
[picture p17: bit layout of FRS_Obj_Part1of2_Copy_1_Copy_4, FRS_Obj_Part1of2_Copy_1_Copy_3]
BO_ 114 FRS_Obj_Part1of2_Copy_1_Copy_4: 8 Vector__XXX
 SG_ FRS_Obj_ExstProb : 41|6@0+ (1.587,0) [0|100] "%" Vector__XXX
 SG_ FRS_Msg_CheckSum : 63|8@0+ (1,0) [0|255] "" Vector__XXX
 SG_ FRS_Msg_AliveCounter : 51|4@0+ (1,0) [0|15] "" Vector__XXX
 SG_ FRS_Obj_XAccRel : 39|7@0+ (0.15,-9.6) [-9.6|9.45] "m/s2" Vector__XXX
 SG_ FRS_Obj_XVelRel_Stdev : 32|7@0+ (0.05,0) [0|6.35] "m/s" Vector__XXX
 SG_ FRS_Obj_YPos_Stdev : 22|7@0+ (0.1,0) [0|12.7] "m" Vector__XXX
 SG_ FRS_Obj_XPos_Stdev : 14|7@0+ (0.1,0) [0|12.7] "m" Vector__XXX
 SG_ FRS_ObjMotionPattern : 31|3@0+ (1,0) [0|7] "" Vector__XXX
 SG_ FRS_Obj_ValidFlag : 23|1@0+ (1,0) [0|1] "" Vector__XXX
 SG_ FRS_Obj_UpdateFlag : 15|1@0+ (1,0) [0|1] "" Vector__XXX
 SG_ FRS_Obj_ObstacleProb : 28|5@0+ (3.226,0) [0|100] "%" Vector__XXX
 SG_ Obj_ID : 7|8@0+ (1,0) [0|255] "" Vector__XXX

BO_ 104 FRS_Obj_Part1of2_Copy_1_Copy_3: 8 Vector__XXX
 SG_ FRS_Obj_ExstProb : 41|6@0+ (1.587,0) [0|100] "%" Vector__XXX
 SG_ FRS_Msg_CheckSum : 63|8@0+ (1,0) [0|255] "" Vector__XXX
 SG_ FRS_Msg_AliveCounter : 51|4@0+ (1,0) [0|15] "" Vector__XXX
 SG_ FRS_Obj_XAccRel : 39|7@0+ (0.15,-9.6) [-9.6|9.45] "m/s2" Vector__XXX
 SG_ FRS_Obj_XVelRel_Stdev : 32|7@0+ (0.05,0) [0|6.35] "m/s" Vector__XXX
 SG_ FRS_Obj_YPos_Stdev : 22|7@0+ (0.1,0) [0|12.7] "m" Vector__XXX
 SG_ FRS_Obj_XPos_Stdev : 14|7@0+ (0.1,0) [0|12.7] "m" Vector__XXX
 SG_ FRS_ObjMotionPattern : 31|3@0+ (1,0) [0|7] "" Vector__XXX
 SG_ FRS_Obj_ValidFlag : 23|1@0+ (1,0) [0|1] "" Vector__XXX
 SG_ FRS_Obj_UpdateFlag : 15|1@0+ (1,0) [0|1] "" Vector__XXX
 SG_ FRS_Obj_ObstacleProb : 28|5@0+ (3.226,0) [0|100] "%" Vector__XXX
 SG_ Obj_ID : 7|8@0+ (1,0) [0|255] "" Vector__XXX

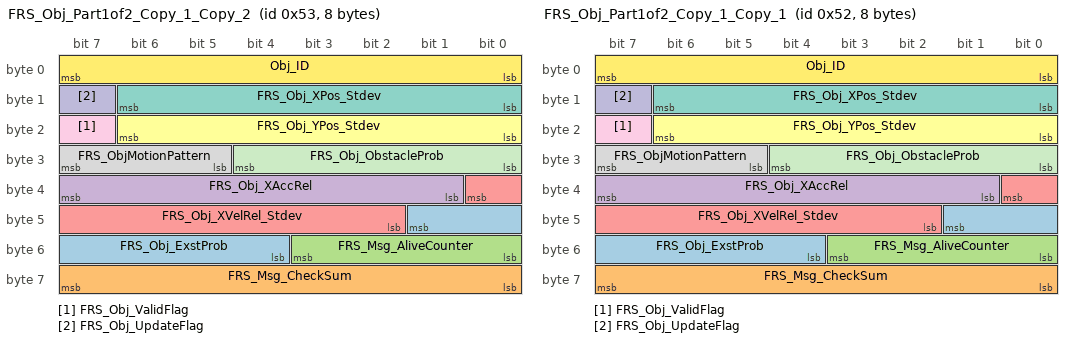
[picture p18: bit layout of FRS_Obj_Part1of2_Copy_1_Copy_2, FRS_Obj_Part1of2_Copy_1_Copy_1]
BO_ 83 FRS_Obj_Part1of2_Copy_1_Copy_2: 8 Vector__XXX
 SG_ FRS_Obj_ExstProb : 41|6@0+ (1.587,0) [0|100] "%" Vector__XXX
 SG_ FRS_Msg_CheckSum : 63|8@0+ (1,0) [0|255] "" Vector__XXX
 SG_ FRS_Msg_AliveCounter : 51|4@0+ (1,0) [0|15] "" Vector__XXX
 SG_ FRS_Obj_XAccRel : 39|7@0+ (0.15,-9.6) [-9.6|9.45] "m/s2" Vector__XXX
 SG_ FRS_Obj_XVelRel_Stdev : 32|7@0+ (0.05,0) [0|6.35] "m/s" Vector__XXX
 SG_ FRS_Obj_YPos_Stdev : 22|7@0+ (0.1,0) [0|12.7] "m" Vector__XXX
 SG_ FRS_Obj_XPos_Stdev : 14|7@0+ (0.1,0) [0|12.7] "m" Vector__XXX
 SG_ FRS_ObjMotionPattern : 31|3@0+ (1,0) [0|7] "" Vector__XXX
 SG_ FRS_Obj_ValidFlag : 23|1@0+ (1,0) [0|1] "" Vector__XXX
 SG_ FRS_Obj_UpdateFlag : 15|1@0+ (1,0) [0|1] "" Vector__XXX
 SG_ FRS_Obj_ObstacleProb : 28|5@0+ (3.226,0) [0|100] "%" Vector__XXX
 SG_ Obj_ID : 7|8@0+ (1,0) [0|255] "" Vector__XXX

BO_ 82 FRS_Obj_Part1of2_Copy_1_Copy_1: 8 Vector__XXX
 SG_ FRS_Obj_ExstProb : 41|6@0+ (1.587,0) [0|100] "%" Vector__XXX
 SG_ FRS_Msg_CheckSum : 63|8@0+ (1,0) [0|255] "" Vector__XXX
 SG_ FRS_Msg_AliveCounter : 51|4@0+ (1,0) [0|15] "" Vector__XXX
 SG_ FRS_Obj_XAccRel : 39|7@0+ (0.15,-9.6) [-9.6|9.45] "m/s2" Vector__XXX
 SG_ FRS_Obj_XVelRel_Stdev : 32|7@0+ (0.05,0) [0|6.35] "m/s" Vector__XXX
 SG_ FRS_Obj_YPos_Stdev : 22|7@0+ (0.1,0) [0|12.7] "m" Vector__XXX
 SG_ FRS_Obj_XPos_Stdev : 14|7@0+ (0.1,0) [0|12.7] "m" Vector__XXX
 SG_ FRS_ObjMotionPattern : 31|3@0+ (1,0) [0|7] "" Vector__XXX
 SG_ FRS_Obj_ValidFlag : 23|1@0+ (1,0) [0|1] "" Vector__XXX
 SG_ FRS_Obj_UpdateFlag : 15|1@0+ (1,0) [0|1] "" Vector__XXX
 SG_ FRS_Obj_ObstacleProb : 28|5@0+ (3.226,0) [0|100] "%" Vector__XXX
 SG_ Obj_ID : 7|8@0+ (1,0) [0|255] "" Vector__XXX

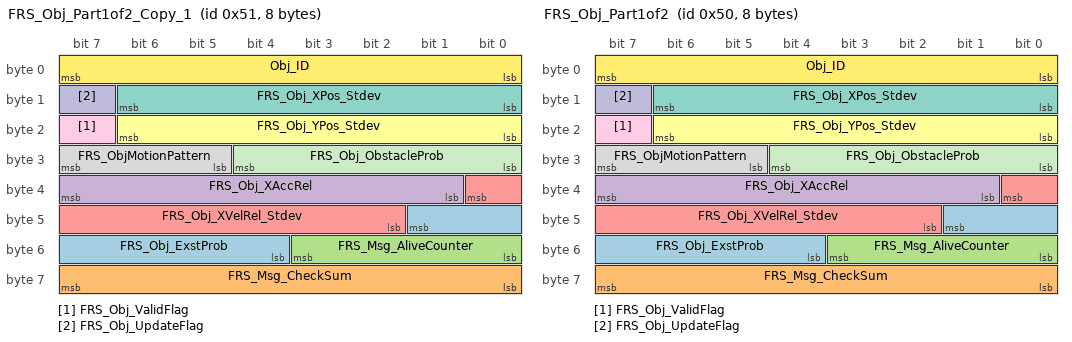
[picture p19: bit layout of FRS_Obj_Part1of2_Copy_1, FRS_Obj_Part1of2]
BO_ 81 FRS_Obj_Part1of2_Copy_1: 8 Vector__XXX
 SG_ FRS_Obj_ExstProb : 41|6@0+ (1.587,0) [0|100] "%" Vector__XXX
 SG_ FRS_Msg_CheckSum : 63|8@0+ (1,0) [0|255] "" Vector__XXX
 SG_ FRS_Msg_AliveCounter : 51|4@0+ (1,0) [0|15] "" Vector__XXX
 SG_ FRS_Obj_XAccRel : 39|7@0+ (0.15,-9.6) [-9.6|9.45] "m/s2" Vector__XXX
 SG_ FRS_Obj_XVelRel_Stdev : 32|7@0+ (0.05,0) [0|6.35] "m/s" Vector__XXX
 SG_ FRS_Obj_YPos_Stdev : 22|7@0+ (0.1,0) [0|12.7] "m" Vector__XXX
 SG_ FRS_Obj_XPos_Stdev : 14|7@0+ (0.1,0) [0|12.7] "m" Vector__XXX
 SG_ FRS_ObjMotionPattern : 31|3@0+ (1,0) [0|7] "" Vector__XXX
 SG_ FRS_Obj_ValidFlag : 23|1@0+ (1,0) [0|1] "" Vector__XXX
 SG_ FRS_Obj_UpdateFlag : 15|1@0+ (1,0) [0|1] "" Vector__XXX
 SG_ FRS_Obj_ObstacleProb : 28|5@0+ (3.226,0) [0|100] "%" Vector__XXX
 SG_ Obj_ID : 7|8@0+ (1,0) [0|255] "" Vector__XXX

BO_ 128 FRS_Status: 8 Vector__XXX
 SG_ FRS_Status_HWErr : 55|1@0+ (1,0) [0|1] "" Vector__XXX
 SG_ FRS_Status_BlkProg : 40|1@0+ (1,0) [0|1] "" Vector__XXX
 SG_ FRS_Status_MisAlign : 54|3@0+ (1,0) [0|7] "" Vector__XXX
 SG_ FRS_Fail : 41|1@0+ (1,0) [0|1] "" Vector__XXX
 SG_ FRS_MeasEnabled : 42|1@0+ (1,0) [0|1] "" Vector__XXX
 SG_ FRS_Host_Yaw : 37|11@0+ (0.1,-102.4) [-102.4|102.3] "deg/s" Vector__XXX
 SG_ FRS_HostSpeed : 17|12@0+ (0.025,-20) [-20|82.375] "m/s" Vector__XXX
 SG_ FRS_TimeStamp : 1|16@0+ (1,0) [0|65535] "s" Vector__XXX
 SG_ FRS_Latency : 7|6@0+ (2,0) [0|126] "ms" Vector__XXX
 SG_ FRS_Msg_CheckSum : 63|8@0+ (1,0) [0|255] "" Vector__XXX
 SG_ FRS_Msg_AliveCounter : 51|4@0+ (1,0) [0|15] "" Vector__XXX

BO_ 32 FRS_Obj_Part2of2: 8 Vector__XXX
 SG_ FRS_Msg_CheckSum : 63|8@0+ (1,0) [0|255] "" Vector__XXX
 SG_ FRS_Msg_AliveCounter : 51|4@0+ (1,0) [0|15] "" Vector__XXX
 SG_ FRS_Obj_MeasFlag : 52|1@0+ (1,0) [0|1] "" Vector__XXX
 SG_ FRS_Obj_YVelRel : 47|11@0+ (0.1,-102.4) [-102.4|102.3] "m/s" Vector__XXX
 SG_ FRS_Obj_Type : 33|2@0+ (1,0) [0|3] "" Vector__XXX
 SG_ FRS_Obj_XPos : 31|14@0+ (0.015625,0) [0|255.984375] "m" Vector__XXX
 SG_ FRS_Obj_YPos : 12|13@0+ (0.015625,-64) [-64|63.984375] "m" Vector__XXX
 SG_ FRS_Obj_XVelRel : 7|11@0+ (0.1,-102.4) [-102.4|102.3] "m/s" Vector__XXX

BO_ 80 FRS_Obj_Part1of2: 8 Vector__XXX
 SG_ FRS_Obj_ExstProb : 41|6@0+ (1.587,0) [0|100] "%" Vector__XXX
 SG_ FRS_Msg_CheckSum : 63|8@0+ (1,0) [0|255] "" Vector__XXX
 SG_ FRS_Msg_AliveCounter : 51|4@0+ (1,0) [0|15] "" Vector__XXX
 SG_ FRS_Obj_XAccRel : 39|7@0+ (0.15,-9.6) [-9.6|9.45] "m/s2" Vector__XXX
 SG_ FRS_Obj_XVelRel_Stdev : 32|7@0+ (0.05,0) [0|6.35] "m/s" Vector__XXX
 SG_ FRS_Obj_YPos_Stdev : 22|7@0+ (0.1,0) [0|12.7] "m" Vector__XXX
 SG_ FRS_Obj_XPos_Stdev : 14|7@0+ (0.1,0) [0|12.7] "m" Vector__XXX
 SG_ FRS_ObjMotionPattern : 31|3@0+ (1,0) [0|7] "" Vector__XXX
 SG_ FRS_Obj_ValidFlag : 23|1@0+ (1,0) [0|1] "" Vector__XXX
 SG_ FRS_Obj_UpdateFlag : 15|1@0+ (1,0) [0|1] "" Vector__XXX
 SG_ FRS_Obj_ObstacleProb : 28|5@0+ (3.226,0) [0|100] "%" Vector__XXX
 SG_ Obj_ID : 7|8@0+ (1,0) [0|255] "" Vector__XXX

CM_ SG_ 65 FRS_Obj_MeasFlag "0x0: object measured in this cycle
0x1: object extrapolated in this cycle";
CM_ SG_ 65 FRS_Obj_Type "0x00: Unknown
0x01: 4 wheeler
0x02: 2 wheeler
0x03: Pedestrian";
CM_ SG_ 64 FRS_Obj_MeasFlag "0x0: object measured in this cycle
0x1: object extrapolated in this cycle";
CM_ SG_ 64 FRS_Obj_Type "0x00: Unknown
0x01: 4 wheeler
0x02: 2 wheeler
0x03: Pedestrian";
CM_ SG_ 63 FRS_Obj_MeasFlag "0x0: object measured in this cycle
0x1: object extrapolated in this cycle";
CM_ SG_ 63 FRS_Obj_Type "0x00: Unknown
0x01: 4 wheeler
0x02: 2 wheeler
0x03: Pedestrian";
CM_ SG_ 62 FRS_Obj_MeasFlag "0x0: object measured in this cycle
0x1: object extrapolated in this cycle";
CM_ SG_ 62 FRS_Obj_Type "0x00: Unknown
0x01: 4 wheeler
0x02: 2 wheeler
0x03: Pedestrian";
CM_ SG_ 61 FRS_Obj_MeasFlag "0x0: object measured in this cycle
0x1: object extrapolated in this cycle";
CM_ SG_ 61 FRS_Obj_Type "0x00: Unknown
0x01: 4 wheeler
0x02: 2 wheeler
0x03: Pedestrian";
CM_ SG_ 60 FRS_Obj_MeasFlag "0x0: object measured in this cycle
0x1: object extrapolated in this cycle";
CM_ SG_ 60 FRS_Obj_Type "0x00: Unknown
0x01: 4 wheeler
0x02: 2 wheeler
0x03: Pedestrian";
CM_ SG_ 59 FRS_Obj_MeasFlag "0x0: object measured in this cycle
0x1: object extrapolated in this cycle";
CM_ SG_ 59 FRS_Obj_Type "0x00: Unknown
0x01: 4 wheeler
0x02: 2 wheeler
0x03: Pedestrian";
CM_ SG_ 58 FRS_Obj_MeasFlag "0x0: object measured in this cycle
0x1: object extrapolated in this cycle";
CM_ SG_ 58 FRS_Obj_Type "0x00: Unknown
0x01: 4 wheeler
0x02: 2 wheeler
0x03: Pedestrian";
CM_ SG_ 57 FRS_Obj_MeasFlag "0x0: object measured in this cycle
0x1: object extrapolated in this cycle";
CM_ SG_ 57 FRS_Obj_Type "0x00: Unknown
0x01: 4 wheeler
0x02: 2 wheeler
0x03: Pedestrian";
CM_ SG_ 56 FRS_Obj_MeasFlag "0x0: object measured in this cycle
0x1: object extrapolated in this cycle";
CM_ SG_ 56 FRS_Obj_Type "0x00: Unknown
0x01: 4 wheeler
0x02: 2 wheeler
0x03: Pedestrian";
CM_ SG_ 54 FRS_Obj_MeasFlag "0x0: object measured in this cycle
0x1: object extrapolated in this cycle";
CM_ SG_ 54 FRS_Obj_Type "0x00: Unknown
0x01: 4 wheeler
0x02: 2 wheeler
0x03: Pedestrian";
CM_ SG_ 53 FRS_Obj_MeasFlag "0x0: object measured in this cycle
0x1: object extrapolated in this cycle";
CM_ SG_ 53 FRS_Obj_Type "0x00: Unknown
0x01: 4 wheeler
0x02: 2 wheeler
0x03: Pedestrian";
CM_ SG_ 52 FRS_Obj_MeasFlag "0x0: object measured in this cycle
0x1: object extrapolated in this cycle";
CM_ SG_ 52 FRS_Obj_Type "0x00: Unknown
0x01: 4 wheeler
0x02: 2 wheeler
0x03: Pedestrian";
CM_ SG_ 51 FRS_Obj_MeasFlag "0x0: object measured in this cycle
0x1: object extrapolated in this cycle";
CM_ SG_ 51 FRS_Obj_Type "0x00: Unknown
0x01: 4 wheeler
0x02: 2 wheeler
0x03: Pedestrian";
CM_ SG_ 50 FRS_Obj_MeasFlag "0x0: object measured in this cycle
0x1: object extrapolated in this cycle";
CM_ SG_ 50 FRS_Obj_Type "0x00: Unknown
0x01: 4 wheeler
0x02: 2 wheeler
0x03: Pedestrian";
CM_ SG_ 49 FRS_Obj_MeasFlag "0x0: object measured in this cycle
0x1: object extrapolated in this cycle";
CM_ SG_ 49 FRS_Obj_Type "0x00: Unknown
0x01: 4 wheeler
0x02: 2 wheeler
0x03: Pedestrian";
CM_ SG_ 48 FRS_Obj_MeasFlag "0x0: object measured in this cycle
0x1: object extrapolated in this cycle";
CM_ SG_ 48 FRS_Obj_Type "0x00: Unknown
0x01: 4 wheeler
0x02: 2 wheeler
0x03: Pedestrian";
CM_ SG_ 47 FRS_Obj_MeasFlag "0x0: object measured in this cycle
0x1: object extrapolated in this cycle";
CM_ SG_ 47 FRS_Obj_Type "0x00: Unknown
0x01: 4 wheeler
0x02: 2 wheeler
0x03: Pedestrian";
CM_ SG_ 46 FRS_Obj_MeasFlag "0x0: object measured in this cycle
0x1: object extrapolated in this cycle";
CM_ SG_ 46 FRS_Obj_Type "0x00: Unknown
0x01: 4 wheeler
0x02: 2 wheeler
0x03: Pedestrian";
CM_ SG_ 45 FRS_Obj_MeasFlag "0x0: object measured in this cycle
0x1: object extrapolated in this cycle";
CM_ SG_ 45 FRS_Obj_Type "0x00: Unknown
0x01: 4 wheeler
0x02: 2 wheeler
0x03: Pedestrian";
CM_ SG_ 43 FRS_Obj_MeasFlag "0x0: object measured in this cycle
0x1: object extrapolated in this cycle";
CM_ SG_ 43 FRS_Obj_Type "0x00: Unknown
0x01: 4 wheeler
0x02: 2 wheeler
0x03: Pedestrian";
CM_ SG_ 42 FRS_Obj_MeasFlag "0x0: object measured in this cycle
0x1: object extrapolated in this cycle";
CM_ SG_ 42 FRS_Obj_Type "0x00: Unknown
0x01: 4 wheeler
0x02: 2 wheeler
0x03: Pedestrian";
CM_ SG_ 41 FRS_Obj_MeasFlag "0x0: object measured in this cycle
0x1: object extrapolated in this cycle";
CM_ SG_ 41 FRS_Obj_Type "0x00: Unknown
0x01: 4 wheeler
0x02: 2 wheeler
0x03: Pedestrian";
CM_ SG_ 40 FRS_Obj_MeasFlag "0x0: object measured in this cycle
0x1: object extrapolated in this cycle";
CM_ SG_ 40 FRS_Obj_Type "0x00: Unknown
0x01: 4 wheeler
0x02: 2 wheeler
0x03: Pedestrian";
CM_ SG_ 39 FRS_Obj_MeasFlag "0x0: object measured in this cycle
0x1: object extrapolated in this cycle";
CM_ SG_ 39 FRS_Obj_Type "0x00: Unknown
0x01: 4 wheeler
0x02: 2 wheeler
0x03: Pedestrian";
CM_ SG_ 38 FRS_Obj_MeasFlag "0x0: object measured in this cycle
0x1: object extrapolated in this cycle";
CM_ SG_ 38 FRS_Obj_Type "0x00: Unknown
0x01: 4 wheeler
0x02: 2 wheeler
0x03: Pedestrian";
CM_ SG_ 37 FRS_Obj_MeasFlag "0x0: object measured in this cycle
0x1: object extrapolated in this cycle";
CM_ SG_ 37 FRS_Obj_Type "0x00: Unknown
0x01: 4 wheeler
0x02: 2 wheeler
0x03: Pedestrian";
CM_ SG_ 36 FRS_Obj_MeasFlag "0x0: object measured in this cycle
0x1: object extrapolated in this cycle";
CM_ SG_ 36 FRS_Obj_Type "0x00: Unknown
0x01: 4 wheeler
0x02: 2 wheeler
0x03: Pedestrian";
CM_ SG_ 35 FRS_Obj_MeasFlag "0x0: object measured in this cycle
0x1: object extrapolated in this cycle";
CM_ SG_ 35 FRS_Obj_Type "0x00: Unknown
0x01: 4 wheeler
0x02: 2 wheeler
0x03: Pedestrian";
CM_ SG_ 34 FRS_Obj_MeasFlag "0x0: object measured in this cycle
0x1: object extrapolated in this cycle";
CM_ SG_ 34 FRS_Obj_Type "0x00: Unknown
0x01: 4 wheeler
0x02: 2 wheeler
0x03: Pedestrian";
CM_ SG_ 71 FRS_Obj_MeasFlag "0x0: object measured in this cycle
0x1: object extrapolated in this cycle";
CM_ SG_ 71 FRS_Obj_Type "0x00: Unknown
0x01: 4 wheeler
0x02: 2 wheeler
0x03: Pedestrian";
CM_ SG_ 70 FRS_Obj_MeasFlag "0x0: object measured in this cycle
0x1: object extrapolated in this cycle";
CM_ SG_ 70 FRS_Obj_Type "0x00: Unknown
0x01: 4 wheeler
0x02: 2 wheeler
0x03: Pedestrian";
CM_ SG_ 69 FRS_Obj_MeasFlag "0x0: object measured in this cycle
0x1: object extrapolated in this cycle";
CM_ SG_ 69 FRS_Obj_Type "0x00: Unknown
0x01: 4 wheeler
0x02: 2 wheeler
0x03: Pedestrian";
CM_ SG_ 68 FRS_Obj_MeasFlag "0x0: object measured in this cycle
0x1: object extrapolated in this cycle";
CM_ SG_ 68 FRS_Obj_Type "0x00: Unknown
0x01: 4 wheeler
0x02: 2 wheeler
0x03: Pedestrian";
CM_ SG_ 67 FRS_Obj_MeasFlag "0x0: object measured in this cycle
0x1: object extrapolated in this cycle";
CM_ SG_ 67 FRS_Obj_Type "0x00: Unknown
0x01: 4 wheeler
0x02: 2 wheeler
0x03: Pedestrian";
CM_ SG_ 66 FRS_Obj_MeasFlag "0x0: object measured in this cycle
0x1: object extrapolated in this cycle";
CM_ SG_ 66 FRS_Obj_Type "0x00: Unknown
0x01: 4 wheeler
0x02: 2 wheeler
0x03: Pedestrian";
CM_ SG_ 55 FRS_Obj_MeasFlag "0x0: object measured in this cycle
0x1: object extrapolated in this cycle";
CM_ SG_ 55 FRS_Obj_Type "0x00: Unknown
0x01: 4 wheeler
0x02: 2 wheeler
0x03: Pedestrian";
CM_ SG_ 44 FRS_Obj_MeasFlag "0x0: object measured in this cycle
0x1: object extrapolated in this cycle";
CM_ SG_ 44 FRS_Obj_Type "0x00: Unknown
0x01: 4 wheeler
0x02: 2 wheeler
0x03: Pedestrian";
CM_ SG_ 33 FRS_Obj_MeasFlag "0x0: object measured in this cycle
0x1: object extrapolated in this cycle";
CM_ SG_ 33 FRS_Obj_Type "0x00: Unknown
0x01: 4 wheeler
0x02: 2 wheeler
0x03: Pedestrian";
CM_ SG_ 113 FRS_ObjMotionPattern "0x00: Unknown
0x01: Stationary
0x02: Stopped
0x03: Moving
0x04: Crossing
0x05-07: reserved";
CM_ SG_ 113 FRS_Obj_ValidFlag "0x0: Object invalid
0x1: Object valid";
CM_ SG_ 113 FRS_Obj_UpdateFlag "Object history flag
0x0: new object in the cycle;
0x1: object existed in previous cycle";
CM_ SG_ 113 Obj_ID "0xFF: Invalid
0x00 - 0xFE: Valid";
CM_ SG_ 112 FRS_ObjMotionPattern "0x00: Unknown
0x01: Stationary
0x02: Stopped
0x03: Moving
0x04: Crossing
0x05-07: reserved";
CM_ SG_ 112 FRS_Obj_ValidFlag "0x0: Object invalid
0x1: Object valid";
CM_ SG_ 112 FRS_Obj_UpdateFlag "Object history flag
0x0: new object in the cycle;
0x1: object existed in previous cycle";
CM_ SG_ 112 Obj_ID "0xFF: Invalid
0x00 - 0xFE: Valid";
CM_ SG_ 111 FRS_ObjMotionPattern "0x00: Unknown
0x01: Stationary
0x02: Stopped
0x03: Moving
0x04: Crossing
0x05-07: reserved";
CM_ SG_ 111 FRS_Obj_ValidFlag "0x0: Object invalid
0x1: Object valid";
CM_ SG_ 111 FRS_Obj_UpdateFlag "Object history flag
0x0: new object in the cycle;
0x1: object existed in previous cycle";
CM_ SG_ 111 Obj_ID "0xFF: Invalid
0x00 - 0xFE: Valid";
CM_ SG_ 110 FRS_ObjMotionPattern "0x00: Unknown
0x01: Stationary
0x02: Stopped
0x03: Moving
0x04: Crossing
0x05-07: reserved";
CM_ SG_ 110 FRS_Obj_ValidFlag "0x0: Object invalid
0x1: Object valid";
CM_ SG_ 110 FRS_Obj_UpdateFlag "Object history flag
0x0: new object in the cycle;
0x1: object existed in previous cycle";
CM_ SG_ 110 Obj_ID "0xFF: Invalid
0x00 - 0xFE: Valid";
CM_ SG_ 109 FRS_ObjMotionPattern "0x00: Unknown
0x01: Stationary
0x02: Stopped
0x03: Moving
0x04: Crossing
0x05-07: reserved";
CM_ SG_ 109 FRS_Obj_ValidFlag "0x0: Object invalid
0x1: Object valid";
CM_ SG_ 109 FRS_Obj_UpdateFlag "Object history flag
0x0: new object in the cycle;
0x1: object existed in previous cycle";
CM_ SG_ 109 Obj_ID "0xFF: Invalid
0x00 - 0xFE: Valid";
CM_ SG_ 108 FRS_ObjMotionPattern "0x00: Unknown
0x01: Stationary
0x02: Stopped
0x03: Moving
0x04: Crossing
0x05-07: reserved";
CM_ SG_ 108 FRS_Obj_ValidFlag "0x0: Object invalid
0x1: Object valid";
CM_ SG_ 108 FRS_Obj_UpdateFlag "Object history flag
0x0: new object in the cycle;
0x1: object existed in previous cycle";
CM_ SG_ 108 Obj_ID "0xFF: Invalid
0x00 - 0xFE: Valid";
CM_ SG_ 107 FRS_ObjMotionPattern "0x00: Unknown
0x01: Stationary
0x02: Stopped
0x03: Moving
0x04: Crossing
0x05-07: reserved";
CM_ SG_ 107 FRS_Obj_ValidFlag "0x0: Object invalid
0x1: Object valid";
CM_ SG_ 107 FRS_Obj_UpdateFlag "Object history flag
0x0: new object in the cycle;
0x1: object existed in previous cycle";
CM_ SG_ 107 Obj_ID "0xFF: Invalid
0x00 - 0xFE: Valid";
CM_ SG_ 106 FRS_ObjMotionPattern "0x00: Unknown
0x01: Stationary
0x02: Stopped
0x03: Moving
0x04: Crossing
0x05-07: reserved";
CM_ SG_ 106 FRS_Obj_ValidFlag "0x0: Object invalid
0x1: Object valid";
CM_ SG_ 106 FRS_Obj_UpdateFlag "Object history flag
0x0: new object in the cycle;
0x1: object existed in previous cycle";
CM_ SG_ 106 Obj_ID "0xFF: Invalid
0x00 - 0xFE: Valid";
CM_ SG_ 105 FRS_ObjMotionPattern "0x00: Unknown
0x01: Stationary
0x02: Stopped
0x03: Moving
0x04: Crossing
0x05-07: reserved";
CM_ SG_ 105 FRS_Obj_ValidFlag "0x0: Object invalid
0x1: Object valid";
CM_ SG_ 105 FRS_Obj_UpdateFlag "Object history flag
0x0: new object in the cycle;
0x1: object existed in previous cycle";
CM_ SG_ 105 Obj_ID "0xFF: Invalid
0x00 - 0xFE: Valid";
CM_ SG_ 103 FRS_ObjMotionPattern "0x00: Unknown
0x01: Stationary
0x02: Stopped
0x03: Moving
0x04: Crossing
0x05-07: reserved";
CM_ SG_ 103 FRS_Obj_ValidFlag "0x0: Object invalid
0x1: Object valid";
CM_ SG_ 103 FRS_Obj_UpdateFlag "Object history flag
0x0: new object in the cycle;
0x1: object existed in previous cycle";
CM_ SG_ 103 Obj_ID "0xFF: Invalid
0x00 - 0xFE: Valid";
CM_ SG_ 102 FRS_ObjMotionPattern "0x00: Unknown
0x01: Stationary
0x02: Stopped
0x03: Moving
0x04: Crossing
0x05-07: reserved";
CM_ SG_ 102 FRS_Obj_ValidFlag "0x0: Object invalid
0x1: Object valid";
CM_ SG_ 102 FRS_Obj_UpdateFlag "Object history flag
0x0: new object in the cycle;
0x1: object existed in previous cycle";
CM_ SG_ 102 Obj_ID "0xFF: Invalid
0x00 - 0xFE: Valid";
CM_ SG_ 101 FRS_ObjMotionPattern "0x00: Unknown
0x01: Stationary
0x02: Stopped
0x03: Moving
0x04: Crossing
0x05-07: reserved";
CM_ SG_ 101 FRS_Obj_ValidFlag "0x0: Object invalid
0x1: Object valid";
CM_ SG_ 101 FRS_Obj_UpdateFlag "Object history flag
0x0: new object in the cycle;
0x1: object existed in previous cycle";
CM_ SG_ 101 Obj_ID "0xFF: Invalid
0x00 - 0xFE: Valid";
CM_ SG_ 100 FRS_ObjMotionPattern "0x00: Unknown
0x01: Stationary
0x02: Stopped
0x03: Moving
0x04: Crossing
0x05-07: reserved";
CM_ SG_ 100 FRS_Obj_ValidFlag "0x0: Object invalid
0x1: Object valid";
CM_ SG_ 100 FRS_Obj_UpdateFlag "Object history flag
0x0: new object in the cycle;
0x1: object existed in previous cycle";
CM_ SG_ 100 Obj_ID "0xFF: Invalid
0x00 - 0xFE: Valid";
CM_ SG_ 99 FRS_ObjMotionPattern "0x00: Unknown
0x01: Stationary
0x02: Stopped
0x03: Moving
0x04: Crossing
0x05-07: reserved";
CM_ SG_ 99 FRS_Obj_ValidFlag "0x0: Object invalid
0x1: Object valid";
CM_ SG_ 99 FRS_Obj_UpdateFlag "Object history flag
0x0: new object in the cycle;
0x1: object existed in previous cycle";
CM_ SG_ 99 Obj_ID "0xFF: Invalid
0x00 - 0xFE: Valid";
CM_ SG_ 98 FRS_ObjMotionPattern "0x00: Unknown
0x01: Stationary
0x02: Stopped
0x03: Moving
0x04: Crossing
0x05-07: reserved";
CM_ SG_ 98 FRS_Obj_ValidFlag "0x0: Object invalid
0x1: Object valid";
CM_ SG_ 98 FRS_Obj_UpdateFlag "Object history flag
0x0: new object in the cycle;
0x1: object existed in previous cycle";
CM_ SG_ 98 Obj_ID "0xFF: Invalid
0x00 - 0xFE: Valid";
CM_ SG_ 97 FRS_ObjMotionPattern "0x00: Unknown
0x01: Stationary
0x02: Stopped
0x03: Moving
0x04: Crossing
0x05-07: reserved";
CM_ SG_ 97 FRS_Obj_ValidFlag "0x0: Object invalid
0x1: Object valid";
CM_ SG_ 97 FRS_Obj_UpdateFlag "Object history flag
0x0: new object in the cycle;
0x1: object existed in previous cycle";
CM_ SG_ 97 Obj_ID "0xFF: Invalid
0x00 - 0xFE: Valid";
CM_ SG_ 96 FRS_ObjMotionPattern "0x00: Unknown
0x01: Stationary
0x02: Stopped
0x03: Moving
0x04: Crossing
0x05-07: reserved";
CM_ SG_ 96 FRS_Obj_ValidFlag "0x0: Object invalid
0x1: Object valid";
CM_ SG_ 96 FRS_Obj_UpdateFlag "Object history flag
0x0: new object in the cycle;
0x1: object existed in previous cycle";
CM_ SG_ 96 Obj_ID "0xFF: Invalid
0x00 - 0xFE: Valid";
CM_ SG_ 95 FRS_ObjMotionPattern "0x00: Unknown
0x01: Stationary
0x02: Stopped
0x03: Moving
0x04: Crossing
0x05-07: reserved";
CM_ SG_ 95 FRS_Obj_ValidFlag "0x0: Object invalid
0x1: Object valid";
CM_ SG_ 95 FRS_Obj_UpdateFlag "Object history flag
0x0: new object in the cycle;
0x1: object existed in previous cycle";
CM_ SG_ 95 Obj_ID "0xFF: Invalid
0x00 - 0xFE: Valid";
CM_ SG_ 94 FRS_ObjMotionPattern "0x00: Unknown
0x01: Stationary
0x02: Stopped
0x03: Moving
0x04: Crossing
0x05-07: reserved";
CM_ SG_ 94 FRS_Obj_ValidFlag "0x0: Object invalid
0x1: Object valid";
CM_ SG_ 94 FRS_Obj_UpdateFlag "Object history flag
0x0: new object in the cycle;
0x1: object existed in previous cycle";
CM_ SG_ 94 Obj_ID "0xFF: Invalid
0x00 - 0xFE: Valid";
CM_ SG_ 93 FRS_ObjMotionPattern "0x00: Unknown
0x01: Stationary
0x02: Stopped
0x03: Moving
0x04: Crossing
0x05-07: reserved";
CM_ SG_ 93 FRS_Obj_ValidFlag "0x0: Object invalid
0x1: Object valid";
CM_ SG_ 93 FRS_Obj_UpdateFlag "Object history flag
0x0: new object in the cycle;
0x1: object existed in previous cycle";
CM_ SG_ 93 Obj_ID "0xFF: Invalid
0x00 - 0xFE: Valid";
CM_ SG_ 92 FRS_ObjMotionPattern "0x00: Unknown
0x01: Stationary
0x02: Stopped
0x03: Moving
0x04: Crossing
0x05-07: reserved";
CM_ SG_ 92 FRS_Obj_ValidFlag "0x0: Object invalid
0x1: Object valid";
CM_ SG_ 92 FRS_Obj_UpdateFlag "Object history flag
0x0: new object in the cycle;
0x1: object existed in previous cycle";
CM_ SG_ 92 Obj_ID "0xFF: Invalid
0x00 - 0xFE: Valid";
CM_ SG_ 91 FRS_ObjMotionPattern "0x00: Unknown
0x01: Stationary
0x02: Stopped
0x03: Moving
0x04: Crossing
0x05-07: reserved";
CM_ SG_ 91 FRS_Obj_ValidFlag "0x0: Object invalid
0x1: Object valid";
CM_ SG_ 91 FRS_Obj_UpdateFlag "Object history flag
0x0: new object in the cycle;
0x1: object existed in previous cycle";
CM_ SG_ 91 Obj_ID "0xFF: Invalid
0x00 - 0xFE: Valid";
CM_ SG_ 90 FRS_ObjMotionPattern "0x00: Unknown
0x01: Stationary
0x02: Stopped
0x03: Moving
0x04: Crossing
0x05-07: reserved";
CM_ SG_ 90 FRS_Obj_ValidFlag "0x0: Object invalid
0x1: Object valid";
CM_ SG_ 90 FRS_Obj_UpdateFlag "Object history flag
0x0: new object in the cycle;
0x1: object existed in previous cycle";
CM_ SG_ 90 Obj_ID "0xFF: Invalid
0x00 - 0xFE: Valid";
CM_ SG_ 89 FRS_ObjMotionPattern "0x00: Unknown
0x01: Stationary
0x02: Stopped
0x03: Moving
0x04: Crossing
0x05-07: reserved";
CM_ SG_ 89 FRS_Obj_ValidFlag "0x0: Object invalid
0x1: Object valid";
CM_ SG_ 89 FRS_Obj_UpdateFlag "Object history flag
0x0: new object in the cycle;
0x1: object existed in previous cycle";
CM_ SG_ 89 Obj_ID "0xFF: Invalid
0x00 - 0xFE: Valid";
CM_ SG_ 88 FRS_ObjMotionPattern "0x00: Unknown
0x01: Stationary
0x02: Stopped
0x03: Moving
0x04: Crossing
0x05-07: reserved";
CM_ SG_ 88 FRS_Obj_ValidFlag "0x0: Object invalid
0x1: Object valid";
CM_ SG_ 88 FRS_Obj_UpdateFlag "Object history flag
0x0: new object in the cycle;
0x1: object existed in previous cycle";
CM_ SG_ 88 Obj_ID "0xFF: Invalid
0x00 - 0xFE: Valid";
CM_ SG_ 87 FRS_ObjMotionPattern "0x00: Unknown
0x01: Stationary
0x02: Stopped
0x03: Moving
0x04: Crossing
0x05-07: reserved";
CM_ SG_ 87 FRS_Obj_ValidFlag "0x0: Object invalid
0x1: Object valid";
CM_ SG_ 87 FRS_Obj_UpdateFlag "Object history flag
0x0: new object in the cycle;
0x1: object existed in previous cycle";
CM_ SG_ 87 Obj_ID "0xFF: Invalid
0x00 - 0xFE: Valid";
CM_ SG_ 86 FRS_ObjMotionPattern "0x00: Unknown
0x01: Stationary
0x02: Stopped
0x03: Moving
0x04: Crossing
0x05-07: reserved";
CM_ SG_ 86 FRS_Obj_ValidFlag "0x0: Object invalid
0x1: Object valid";
CM_ SG_ 86 FRS_Obj_UpdateFlag "Object history flag
0x0: new object in the cycle;
0x1: object existed in previous cycle";
CM_ SG_ 86 Obj_ID "0xFF: Invalid
0x00 - 0xFE: Valid";
CM_ SG_ 85 FRS_ObjMotionPattern "0x00: Unknown
0x01: Stationary
0x02: Stopped
0x03: Moving
0x04: Crossing
0x05-07: reserved";
CM_ SG_ 85 FRS_Obj_ValidFlag "0x0: Object invalid
0x1: Object valid";
CM_ SG_ 85 FRS_Obj_UpdateFlag "Object history flag
0x0: new object in the cycle;
0x1: object existed in previous cycle";
CM_ SG_ 85 Obj_ID "0xFF: Invalid
0x00 - 0xFE: Valid";
CM_ SG_ 84 FRS_ObjMotionPattern "0x00: Unknown
0x01: Stationary
0x02: Stopped
0x03: Moving
0x04: Crossing
0x05-07: reserved";
CM_ SG_ 84 FRS_Obj_ValidFlag "0x0: Object invalid
0x1: Object valid";
CM_ SG_ 84 FRS_Obj_UpdateFlag "Object history flag
0x0: new object in the cycle;
0x1: object existed in previous cycle";
CM_ SG_ 84 Obj_ID "0xFF: Invalid
0x00 - 0xFE: Valid";
CM_ SG_ 119 FRS_ObjMotionPattern "0x00: Unknown
0x01: Stationary
0x02: Stopped
0x03: Moving
0x04: Crossing
0x05-07: reserved";
CM_ SG_ 119 FRS_Obj_ValidFlag "0x0: Object invalid
0x1: Object valid";
CM_ SG_ 119 FRS_Obj_UpdateFlag "Object history flag
0x0: new object in the cycle;
0x1: object existed in previous cycle";
CM_ SG_ 119 Obj_ID "0xFF: Invalid
0x00 - 0xFE: Valid";
CM_ SG_ 118 FRS_ObjMotionPattern "0x00: Unknown
0x01: Stationary
0x02: Stopped
0x03: Moving
0x04: Crossing
0x05-07: reserved";
CM_ SG_ 118 FRS_Obj_ValidFlag "0x0: Object invalid
0x1: Object valid";
CM_ SG_ 118 FRS_Obj_UpdateFlag "Object history flag
0x0: new object in the cycle;
0x1: object existed in previous cycle";
CM_ SG_ 118 Obj_ID "0xFF: Invalid
0x00 - 0xFE: Valid";
CM_ SG_ 117 FRS_ObjMotionPattern "0x00: Unknown
0x01: Stationary
0x02: Stopped
0x03: Moving
0x04: Crossing
0x05-07: reserved";
CM_ SG_ 117 FRS_Obj_ValidFlag "0x0: Object invalid
0x1: Object valid";
CM_ SG_ 117 FRS_Obj_UpdateFlag "Object history flag
0x0: new object in the cycle;
0x1: object existed in previous cycle";
CM_ SG_ 117 Obj_ID "0xFF: Invalid
0x00 - 0xFE: Valid";
CM_ SG_ 116 FRS_ObjMotionPattern "0x00: Unknown
0x01: Stationary
0x02: Stopped
0x03: Moving
0x04: Crossing
0x05-07: reserved";
CM_ SG_ 116 FRS_Obj_ValidFlag "0x0: Object invalid
0x1: Object valid";
CM_ SG_ 116 FRS_Obj_UpdateFlag "Object history flag
0x0: new object in the cycle;
0x1: object existed in previous cycle";
CM_ SG_ 116 Obj_ID "0xFF: Invalid
0x00 - 0xFE: Valid";
CM_ SG_ 115 FRS_ObjMotionPattern "0x00: Unknown
0x01: Stationary
0x02: Stopped
0x03: Moving
0x04: Crossing
0x05-07: reserved";
CM_ SG_ 115 FRS_Obj_ValidFlag "0x0: Object invalid
0x1: Object valid";
CM_ SG_ 115 FRS_Obj_UpdateFlag "Object history flag
0x0: new object in the cycle;
0x1: object existed in previous cycle";
CM_ SG_ 115 Obj_ID "0xFF: Invalid
0x00 - 0xFE: Valid";
CM_ SG_ 114 FRS_ObjMotionPattern "0x00: Unknown
0x01: Stationary
0x02: Stopped
0x03: Moving
0x04: Crossing
0x05-07: reserved";
CM_ SG_ 114 FRS_Obj_ValidFlag "0x0: Object invalid
0x1: Object valid";
CM_ SG_ 114 FRS_Obj_UpdateFlag "Object history flag
0x0: new object in the cycle;
0x1: object existed in previous cycle";
CM_ SG_ 114 Obj_ID "0xFF: Invalid
0x00 - 0xFE: Valid";
CM_ SG_ 104 FRS_ObjMotionPattern "0x00: Unknown
0x01: Stationary
0x02: Stopped
0x03: Moving
0x04: Crossing
0x05-07: reserved";
CM_ SG_ 104 FRS_Obj_ValidFlag "0x0: Object invalid
0x1: Object valid";
CM_ SG_ 104 FRS_Obj_UpdateFlag "Object history flag
0x0: new object in the cycle;
0x1: object existed in previous cycle";
CM_ SG_ 104 Obj_ID "0xFF: Invalid
0x00 - 0xFE: Valid";
CM_ SG_ 83 FRS_ObjMotionPattern "0x00: Unknown
0x01: Stationary
0x02: Stopped
0x03: Moving
0x04: Crossing
0x05-07: reserved";
CM_ SG_ 83 FRS_Obj_ValidFlag "0x0: Object invalid
0x1: Object valid";
CM_ SG_ 83 FRS_Obj_UpdateFlag "Object history flag
0x0: new object in the cycle;
0x1: object existed in previous cycle";
CM_ SG_ 83 Obj_ID "0xFF: Invalid
0x00 - 0xFE: Valid";
CM_ SG_ 82 FRS_ObjMotionPattern "0x00: Unknown
0x01: Stationary
0x02: Stopped
0x03: Moving
0x04: Crossing
0x05-07: reserved";
CM_ SG_ 82 FRS_Obj_ValidFlag "0x0: Object invalid
0x1: Object valid";
CM_ SG_ 82 FRS_Obj_UpdateFlag "Object history flag
0x0: new object in the cycle;
0x1: object existed in previous cycle";
CM_ SG_ 82 Obj_ID "0xFF: Invalid
0x00 - 0xFE: Valid";
CM_ SG_ 81 FRS_ObjMotionPattern "0x00: Unknown
0x01: Stationary
0x02: Stopped
0x03: Moving
0x04: Crossing
0x05-07: reserved";
CM_ SG_ 81 FRS_Obj_ValidFlag "0x0: Object invalid
0x1: Object valid";
CM_ SG_ 81 FRS_Obj_UpdateFlag "Object history flag
0x0: new object in the cycle;
0x1: object existed in previous cycle";
CM_ SG_ 81 Obj_ID "0xFF: Invalid
0x00 - 0xFE: Valid";
CM_ SG_ 128 FRS_Status_HWErr "0x0:HW is NOT failed
0x1:HW is failed";
CM_ SG_ 128 FRS_Status_BlkProg "0x0: FRS is NOT blocked
0x1: FRS is blocked";
CM_ SG_ 128 FRS_Status_MisAlign "0x00£ºunknown
0x01£ºcalibrated
0x02£ºsensor mis-alignment detected
0x03£ºcalibration in progress
0x04£ºuncalibratable
0x05-07:  reserved";
CM_ SG_ 128 FRS_Fail "0x0 = FRS radar is NOT working
0x1 = FRS radar is working";
CM_ SG_ 128 FRS_MeasEnabled "0x00 = measurement disabled = FRS_Fail
0x01 = measurement enabled =FRS not Fail";
CM_ SG_ 32 FRS_Obj_MeasFlag "0x0: object measured in this cycle
0x1: object extrapolated in this cycle";
CM_ SG_ 32 FRS_Obj_Type "0x00: Unknown
0x01: 4 wheeler
0x02: 2 wheeler
0x03: Pedestrian";
CM_ SG_ 80 FRS_ObjMotionPattern "0x00: Unknown
0x01: Stationary
0x02: Stopped
0x03: Moving
0x04: Crossing
0x05-07: reserved";
CM_ SG_ 80 FRS_Obj_ValidFlag "0x0: Object invalid
0x1: Object valid";
CM_ SG_ 80 FRS_Obj_UpdateFlag "Object history flag
0x0: new object in the cycle;
0x1: object existed in previous cycle";
CM_ SG_ 80 Obj_ID "0xFF: Invalid
0x00 - 0xFE: Valid";
BA_DEF_  "BusType" STRING ;
BA_DEF_DEF_  "BusType" "CAN";
